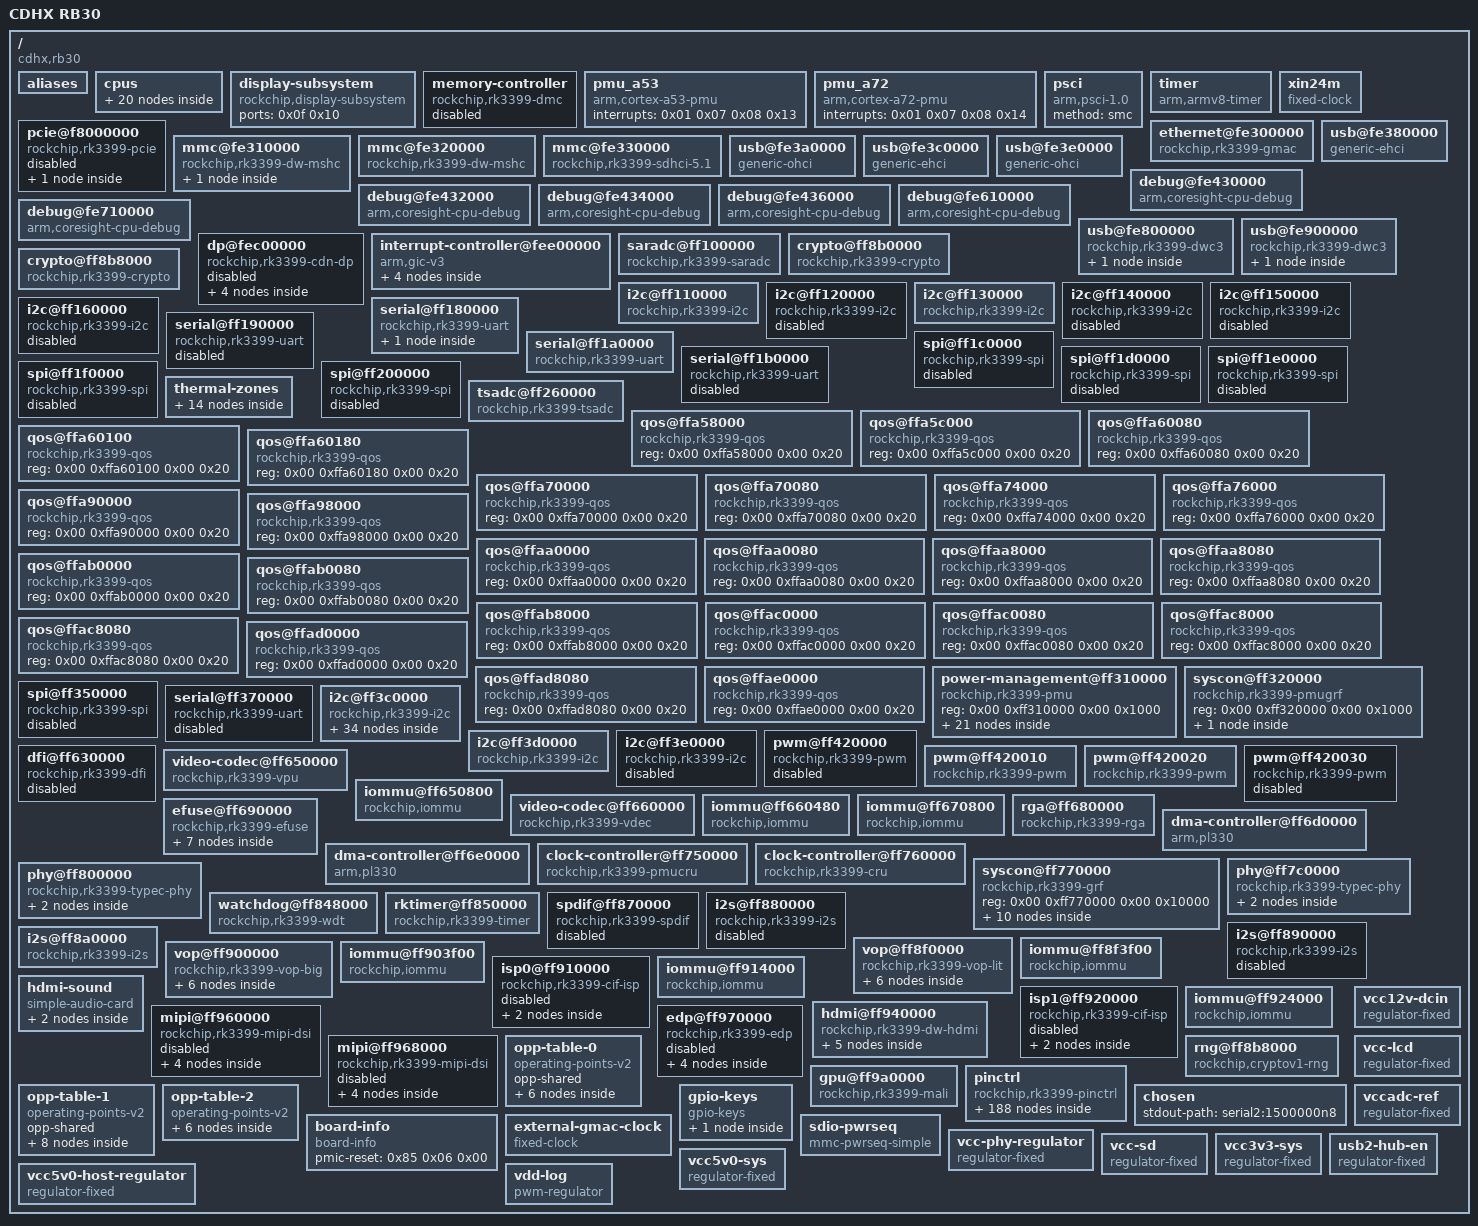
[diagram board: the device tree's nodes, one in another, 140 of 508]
/dts-v1/;

/ {
	compatible = "cdhx,rb30", "rockchip,rk3399";
	interrupt-parent = <0x01>;
	#address-cells = <0x02>;
	#size-cells = <0x02>;
	model = "CDHX RB30";

	aliases {
		ethernet0 = "/ethernet@fe300000";
		i2c0 = "/i2c@ff3c0000";
		i2c1 = "/i2c@ff110000";
		i2c2 = "/i2c@ff120000";
		i2c3 = "/i2c@ff130000";
		i2c4 = "/i2c@ff3d0000";
		i2c5 = "/i2c@ff140000";
		i2c6 = "/i2c@ff150000";
		i2c7 = "/i2c@ff160000";
		i2c8 = "/i2c@ff3e0000";
		mmc0 = "/mmc@fe310000";
		mmc1 = "/mmc@fe320000";
		mmc2 = "/mmc@fe330000";
		serial0 = "/serial@ff180000";
		serial1 = "/serial@ff190000";
		serial2 = "/serial@ff1a0000";
		serial3 = "/serial@ff1b0000";
		serial4 = "/serial@ff370000";
	};

	cpus {
		#address-cells = <0x02>;
		#size-cells = <0x00>;

		cpu-map {

			cluster0 {

				core0 {
					cpu = <0x02>;
				};

				core1 {
					cpu = <0x03>;
				};

				core2 {
					cpu = <0x04>;
				};

				core3 {
					cpu = <0x05>;
				};
			};

			cluster1 {

				core0 {
					cpu = <0x06>;
				};

				core1 {
					cpu = <0x07>;
				};
			};
		};

		cpu@0 {
			device_type = "cpu";
			compatible = "arm,cortex-a53";
			reg = <0x00 0x00>;
			enable-method = "psci";
			capacity-dmips-mhz = <0x1e5>;
			clocks = <0x08 0x08>;
			#cooling-cells = <0x02>;
			dynamic-power-coefficient = <0x64>;
			cpu-idle-states = <0x09 0x0a>;
			operating-points-v2 = <0x0b>;
			cpu-supply = <0x0c>;
			phandle = <0x02>;
		};

		cpu@1 {
			device_type = "cpu";
			compatible = "arm,cortex-a53";
			reg = <0x00 0x01>;
			enable-method = "psci";
			capacity-dmips-mhz = <0x1e5>;
			clocks = <0x08 0x08>;
			#cooling-cells = <0x02>;
			dynamic-power-coefficient = <0x64>;
			cpu-idle-states = <0x09 0x0a>;
			operating-points-v2 = <0x0b>;
			cpu-supply = <0x0c>;
			phandle = <0x03>;
		};

		cpu@2 {
			device_type = "cpu";
			compatible = "arm,cortex-a53";
			reg = <0x00 0x02>;
			enable-method = "psci";
			capacity-dmips-mhz = <0x1e5>;
			clocks = <0x08 0x08>;
			#cooling-cells = <0x02>;
			dynamic-power-coefficient = <0x64>;
			cpu-idle-states = <0x09 0x0a>;
			operating-points-v2 = <0x0b>;
			cpu-supply = <0x0c>;
			phandle = <0x04>;
		};

		cpu@3 {
			device_type = "cpu";
			compatible = "arm,cortex-a53";
			reg = <0x00 0x03>;
			enable-method = "psci";
			capacity-dmips-mhz = <0x1e5>;
			clocks = <0x08 0x08>;
			#cooling-cells = <0x02>;
			dynamic-power-coefficient = <0x64>;
			cpu-idle-states = <0x09 0x0a>;
			operating-points-v2 = <0x0b>;
			cpu-supply = <0x0c>;
			phandle = <0x05>;
		};

		cpu@100 {
			device_type = "cpu";
			compatible = "arm,cortex-a72";
			reg = <0x00 0x100>;
			enable-method = "psci";
			capacity-dmips-mhz = <0x400>;
			clocks = <0x08 0x09>;
			#cooling-cells = <0x02>;
			dynamic-power-coefficient = <0x1b4>;
			cpu-idle-states = <0x09 0x0a>;
			operating-points-v2 = <0x0d>;
			cpu-supply = <0x0e>;
			phandle = <0x06>;

			thermal-idle {
				#cooling-cells = <0x02>;
				duration-us = <0x2710>;
				exit-latency-us = <0x1f4>;
			};
		};

		cpu@101 {
			device_type = "cpu";
			compatible = "arm,cortex-a72";
			reg = <0x00 0x101>;
			enable-method = "psci";
			capacity-dmips-mhz = <0x400>;
			clocks = <0x08 0x09>;
			#cooling-cells = <0x02>;
			dynamic-power-coefficient = <0x1b4>;
			cpu-idle-states = <0x09 0x0a>;
			operating-points-v2 = <0x0d>;
			cpu-supply = <0x0e>;
			phandle = <0x07>;

			thermal-idle {
				#cooling-cells = <0x02>;
				duration-us = <0x2710>;
				exit-latency-us = <0x1f4>;
			};
		};

		idle-states {
			entry-method = "psci";

			cpu-sleep {
				compatible = "arm,idle-state";
				local-timer-stop;
				arm,psci-suspend-param = <0x10000>;
				entry-latency-us = <0x78>;
				exit-latency-us = <0xfa>;
				min-residency-us = <0x384>;
				phandle = <0x09>;
			};

			cluster-sleep {
				compatible = "arm,idle-state";
				local-timer-stop;
				arm,psci-suspend-param = <0x1010000>;
				entry-latency-us = <0x190>;
				exit-latency-us = <0x1f4>;
				min-residency-us = <0x7d0>;
				phandle = <0x0a>;
			};
		};
	};

	display-subsystem {
		compatible = "rockchip,display-subsystem";
		ports = <0x0f 0x10>;
	};

	memory-controller {
		compatible = "rockchip,rk3399-dmc";
		rockchip,pmu = <0x11>;
		devfreq-events = <0x12>;
		clocks = <0x08 0xa8>;
		clock-names = "dmc_clk";
		status = "disabled";
		phandle = <0xc7>;
	};

	pmu_a53 {
		compatible = "arm,cortex-a53-pmu";
		interrupts = <0x01 0x07 0x08 0x13>;
	};

	pmu_a72 {
		compatible = "arm,cortex-a72-pmu";
		interrupts = <0x01 0x07 0x08 0x14>;
	};

	psci {
		compatible = "arm,psci-1.0";
		method = "smc";
	};

	timer {
		compatible = "arm,armv8-timer";
		interrupts = <0x01 0x0d 0x08 0x00 0x01 0x0e 0x08 0x00 0x01 0x0b 0x08 0x00 0x01 0x0a 0x08 0x00>;
		arm,no-tick-in-suspend;
	};

	xin24m {
		compatible = "fixed-clock";
		clock-frequency = <0x16e3600>;
		clock-output-names = "xin24m";
		#clock-cells = <0x00>;
		phandle = <0x92>;
	};

	pcie@f8000000 {
		compatible = "rockchip,rk3399-pcie";
		reg = <0x00 0xf8000000 0x00 0x2000000 0x00 0xfd000000 0x00 0x1000000>;
		reg-names = "axi-base", "apb-base";
		device_type = "pci";
		#address-cells = <0x03>;
		#size-cells = <0x02>;
		#interrupt-cells = <0x01>;
		aspm-no-l0s;
		bus-range = <0x00 0x1f>;
		clocks = <0x08 0xc5 0x08 0xc4 0x08 0x147 0x08 0xa0>;
		clock-names = "aclk", "aclk-perf", "hclk", "pm";
		interrupts = <0x00 0x31 0x04 0x00 0x00 0x32 0x04 0x00 0x00 0x33 0x04 0x00>;
		interrupt-names = "sys", "legacy", "client";
		interrupt-map-mask = <0x00 0x00 0x00 0x07>;
		interrupt-map = <0x00 0x00 0x00 0x01 0x15 0x00 0x00 0x00 0x00 0x02 0x15 0x01 0x00 0x00 0x00 0x03 0x15 0x02 0x00 0x00 0x00 0x04 0x15 0x03>;
		max-link-speed = <0x01>;
		msi-map = <0x00 0x16 0x00 0x1000>;
		phys = <0x17 0x00 0x17 0x01 0x17 0x02 0x17 0x03>;
		phy-names = "pcie-phy-0", "pcie-phy-1", "pcie-phy-2", "pcie-phy-3";
		ranges = <0x82000000 0x00 0xfa000000 0x00 0xfa000000 0x00 0x1e00000 0x81000000 0x00 0xfbe00000 0x00 0xfbe00000 0x00 0x100000>;
		resets = <0x08 0x82 0x08 0x83 0x08 0x84 0x08 0x85 0x08 0x86 0x08 0x81 0x08 0x80>;
		reset-names = "core", "mgmt", "mgmt-sticky", "pipe", "pm", "pclk", "aclk";
		status = "disabled";
		phandle = <0xc8>;

		interrupt-controller {
			interrupt-controller;
			#address-cells = <0x00>;
			#interrupt-cells = <0x01>;
			phandle = <0x15>;
		};
	};

	ethernet@fe300000 {
		compatible = "rockchip,rk3399-gmac";
		reg = <0x00 0xfe300000 0x00 0x10000>;
		interrupts = <0x00 0x0c 0x04 0x00>;
		interrupt-names = "macirq";
		clocks = <0x08 0x69 0x08 0x67 0x08 0x68 0x08 0x66 0x08 0x6a 0x08 0xd5 0x08 0x166>;
		clock-names = "stmmaceth", "mac_clk_rx", "mac_clk_tx", "clk_mac_ref", "clk_mac_refout", "aclk_mac", "pclk_mac";
		power-domains = <0x18 0x16>;
		resets = <0x08 0x89>;
		reset-names = "stmmaceth";
		rockchip,grf = <0x19>;
		snps,txpbl = <0x04>;
		status = "okay";
		assigned-clocks = <0x08 0xa6>;
		assigned-clock-parents = <0x1a>;
		clock_in_out = "input";
		phy-supply = <0x1b>;
		phy-mode = "rgmii";
		pinctrl-names = "default";
		pinctrl-0 = <0x1c>;
		snps,reset-gpio = <0x1d 0x0f 0x01>;
		snps,reset-active-low;
		snps,reset-delays-us = <0x00 0x2710 0xc350>;
		tx_delay = <0x28>;
		rx_delay = <0x11>;
		phandle = <0xc9>;
	};

	mmc@fe310000 {
		compatible = "rockchip,rk3399-dw-mshc", "rockchip,rk3288-dw-mshc";
		reg = <0x00 0xfe310000 0x00 0x4000>;
		interrupts = <0x00 0x40 0x04 0x00>;
		max-frequency = <0x8f0d180>;
		clocks = <0x08 0x1ee 0x08 0x4d 0x08 0x9c 0x08 0x9d>;
		clock-names = "biu", "ciu", "ciu-drive", "ciu-sample";
		fifo-depth = <0x100>;
		power-domains = <0x18 0x1c>;
		resets = <0x08 0x79>;
		reset-names = "reset";
		status = "okay";
		#address-cells = <0x01>;
		#size-cells = <0x00>;
		bus-width = <0x04>;
		clock-frequency = <0x2faf080>;
		cap-sdio-irq;
		cap-sd-highspeed;
		keep-power-in-suspend;
		mmc-pwrseq = <0x1e>;
		non-removable;
		pinctrl-names = "default";
		pinctrl-0 = <0x1f 0x20 0x21>;
		sd-uhs-sdr104;
		phandle = <0xca>;

		wifi@1 {
			compatible = "brcm,bcm43455-fmac";
			reg = <0x01>;
			interrupt-parent = <0x22>;
			interrupts = <0x03 0x00>;
			interrupt-names = "host-wake";
			pinctrl-names = "default";
			pinctrl-0 = <0x23>;
			phandle = <0xcb>;
		};
	};

	mmc@fe320000 {
		compatible = "rockchip,rk3399-dw-mshc", "rockchip,rk3288-dw-mshc";
		reg = <0x00 0xfe320000 0x00 0x4000>;
		interrupts = <0x00 0x41 0x04 0x00>;
		max-frequency = <0x8f0d180>;
		assigned-clocks = <0x08 0x1cd>;
		assigned-clock-rates = <0xbebc200>;
		clocks = <0x08 0x1ce 0x08 0x4c 0x08 0x9a 0x08 0x9b>;
		clock-names = "biu", "ciu", "ciu-drive", "ciu-sample";
		fifo-depth = <0x100>;
		power-domains = <0x18 0x1b>;
		resets = <0x08 0x7a>;
		reset-names = "reset";
		status = "okay";
		clock-frequency = <0x8f0d180>;
		clock-freq-min-max = <0x186a0 0x8f0d180>;
		supports-sd;
		bus-width = <0x04>;
		cap-mmc-highspeed;
		cap-sd-highspeed;
		disable-wp;
		num-slots = <0x01>;
		sd-uhs-sdr104;
		vmmc-supply = <0x24>;
		vqmmc-supply = <0x25>;
		pinctrl-names = "default";
		pinctrl-0 = <0x26 0x27 0x28 0x29>;
		phandle = <0xcc>;
	};

	mmc@fe330000 {
		compatible = "rockchip,rk3399-sdhci-5.1", "arasan,sdhci-5.1";
		reg = <0x00 0xfe330000 0x00 0x10000>;
		interrupts = <0x00 0x0b 0x04 0x00>;
		arasan,soc-ctl-syscon = <0x19>;
		assigned-clocks = <0x08 0x4e>;
		assigned-clock-rates = <0xbebc200>;
		clocks = <0x08 0x4e 0x08 0xf0>;
		clock-names = "clk_xin", "clk_ahb";
		clock-output-names = "emmc_cardclock";
		#clock-cells = <0x00>;
		phys = <0x2a>;
		phy-names = "phy_arasan";
		power-domains = <0x18 0x17>;
		disable-cqe-dcmd;
		status = "okay";
		bus-width = <0x08>;
		mmc-hs200-enhanced-strobe;
		non-removable;
		phandle = <0x95>;
	};

	usb@fe380000 {
		compatible = "generic-ehci";
		reg = <0x00 0xfe380000 0x00 0x20000>;
		interrupts = <0x00 0x1a 0x04 0x00>;
		clocks = <0x08 0x1c8 0x08 0x1c9 0x2b>;
		phys = <0x2c>;
		phy-names = "usb";
		status = "okay";
		phandle = <0xcd>;
	};

	usb@fe3a0000 {
		compatible = "generic-ohci";
		reg = <0x00 0xfe3a0000 0x00 0x20000>;
		interrupts = <0x00 0x1c 0x04 0x00>;
		clocks = <0x08 0x1c8 0x08 0x1c9 0x2b>;
		phys = <0x2c>;
		phy-names = "usb";
		status = "okay";
		phandle = <0xce>;
	};

	usb@fe3c0000 {
		compatible = "generic-ehci";
		reg = <0x00 0xfe3c0000 0x00 0x20000>;
		interrupts = <0x00 0x1e 0x04 0x00>;
		clocks = <0x08 0x1ca 0x08 0x1cb 0x2d>;
		phys = <0x2e>;
		phy-names = "usb";
		status = "okay";
		phandle = <0xcf>;
	};

	usb@fe3e0000 {
		compatible = "generic-ohci";
		reg = <0x00 0xfe3e0000 0x00 0x20000>;
		interrupts = <0x00 0x20 0x04 0x00>;
		clocks = <0x08 0x1ca 0x08 0x1cb 0x2d>;
		phys = <0x2e>;
		phy-names = "usb";
		status = "okay";
		phandle = <0xd0>;
	};

	debug@fe430000 {
		compatible = "arm,coresight-cpu-debug", "arm,primecell";
		reg = <0x00 0xfe430000 0x00 0x1000>;
		clocks = <0x08 0x14d>;
		clock-names = "apb_pclk";
		cpu = <0x02>;
	};

	debug@fe432000 {
		compatible = "arm,coresight-cpu-debug", "arm,primecell";
		reg = <0x00 0xfe432000 0x00 0x1000>;
		clocks = <0x08 0x14d>;
		clock-names = "apb_pclk";
		cpu = <0x03>;
	};

	debug@fe434000 {
		compatible = "arm,coresight-cpu-debug", "arm,primecell";
		reg = <0x00 0xfe434000 0x00 0x1000>;
		clocks = <0x08 0x14d>;
		clock-names = "apb_pclk";
		cpu = <0x04>;
	};

	debug@fe436000 {
		compatible = "arm,coresight-cpu-debug", "arm,primecell";
		reg = <0x00 0xfe436000 0x00 0x1000>;
		clocks = <0x08 0x14d>;
		clock-names = "apb_pclk";
		cpu = <0x05>;
	};

	debug@fe610000 {
		compatible = "arm,coresight-cpu-debug", "arm,primecell";
		reg = <0x00 0xfe610000 0x00 0x1000>;
		clocks = <0x08 0x14c>;
		clock-names = "apb_pclk";
		cpu = <0x06>;
	};

	debug@fe710000 {
		compatible = "arm,coresight-cpu-debug", "arm,primecell";
		reg = <0x00 0xfe710000 0x00 0x1000>;
		clocks = <0x08 0x14c>;
		clock-names = "apb_pclk";
		cpu = <0x07>;
	};

	usb@fe800000 {
		compatible = "rockchip,rk3399-dwc3";
		#address-cells = <0x02>;
		#size-cells = <0x02>;
		ranges;
		clocks = <0x08 0x81 0x08 0x83 0x08 0xf6 0x08 0xf8 0x08 0xf4 0x08 0xf9>;
		clock-names = "ref_clk", "suspend_clk", "bus_clk", "aclk_usb3_rksoc_axi_perf", "aclk_usb3", "grf_clk";
		resets = <0x08 0x125>;
		reset-names = "usb3-otg";
		status = "okay";
		phandle = <0xd1>;

		usb@fe800000 {
			compatible = "snps,dwc3";
			reg = <0x00 0xfe800000 0x00 0x100000>;
			interrupts = <0x00 0x69 0x04 0x00>;
			clocks = <0x08 0x81 0x08 0xf6 0x08 0x83>;
			clock-names = "ref", "bus_early", "suspend";
			dr_mode = "host";
			phys = <0x2f 0x30>;
			phy-names = "usb2-phy", "usb3-phy";
			phy_type = "utmi_wide";
			snps,dis_enblslpm_quirk;
			snps,dis-u2-freeclk-exists-quirk;
			snps,dis_u2_susphy_quirk;
			snps,dis-del-phy-power-chg-quirk;
			snps,dis-tx-ipgap-linecheck-quirk;
			power-domains = <0x18 0x18>;
			status = "okay";
			phandle = <0xd2>;
		};
	};

	usb@fe900000 {
		compatible = "rockchip,rk3399-dwc3";
		#address-cells = <0x02>;
		#size-cells = <0x02>;
		ranges;
		clocks = <0x08 0x82 0x08 0x84 0x08 0xf7 0x08 0xf8 0x08 0xf4 0x08 0xf9>;
		clock-names = "ref_clk", "suspend_clk", "bus_clk", "aclk_usb3_rksoc_axi_perf", "aclk_usb3", "grf_clk";
		resets = <0x08 0x126>;
		reset-names = "usb3-otg";
		status = "okay";
		phandle = <0xd3>;

		usb@fe900000 {
			compatible = "snps,dwc3";
			reg = <0x00 0xfe900000 0x00 0x100000>;
			interrupts = <0x00 0x6e 0x04 0x00>;
			clocks = <0x08 0x82 0x08 0xf7 0x08 0x84>;
			clock-names = "ref", "bus_early", "suspend";
			dr_mode = "host";
			phys = <0x31 0x32>;
			phy-names = "usb2-phy", "usb3-phy";
			phy_type = "utmi_wide";
			snps,dis_enblslpm_quirk;
			snps,dis-u2-freeclk-exists-quirk;
			snps,dis_u2_susphy_quirk;
			snps,dis-del-phy-power-chg-quirk;
			snps,dis-tx-ipgap-linecheck-quirk;
			power-domains = <0x18 0x18>;
			status = "okay";
			phandle = <0xd4>;
		};
	};

	dp@fec00000 {
		compatible = "rockchip,rk3399-cdn-dp";
		reg = <0x00 0xfec00000 0x00 0x100000>;
		interrupts = <0x00 0x09 0x04 0x00>;
		assigned-clocks = <0x08 0x72 0x08 0xa1>;
		assigned-clock-rates = <0x5f5e100 0xbebc200>;
		clocks = <0x08 0x72 0x08 0x175 0x08 0xa1 0x08 0x16f>;
		clock-names = "core-clk", "pclk", "spdif", "grf";
		phys = <0x33 0x34>;
		power-domains = <0x18 0x15>;
		resets = <0x08 0x103 0x08 0x148 0x08 0x14a 0x08 0xfd>;
		reset-names = "spdif", "dptx", "apb", "core";
		rockchip,grf = <0x19>;
		#sound-dai-cells = <0x01>;
		status = "disabled";
		phandle = <0xd5>;

		ports {

			port {
				#address-cells = <0x01>;
				#size-cells = <0x00>;
				phandle = <0xd6>;

				endpoint@0 {
					reg = <0x00>;
					remote-endpoint = <0x35>;
					phandle = <0xa5>;
				};

				endpoint@1 {
					reg = <0x01>;
					remote-endpoint = <0x36>;
					phandle = <0x9f>;
				};
			};
		};
	};

	interrupt-controller@fee00000 {
		compatible = "arm,gic-v3";
		#interrupt-cells = <0x04>;
		#address-cells = <0x02>;
		#size-cells = <0x02>;
		ranges;
		interrupt-controller;
		reg = <0x00 0xfee00000 0x00 0x10000 0x00 0xfef00000 0x00 0xc0000 0x00 0xfff00000 0x00 0x10000 0x00 0xfff10000 0x00 0x10000 0x00 0xfff20000 0x00 0x10000>;
		interrupts = <0x01 0x09 0x04 0x00>;
		phandle = <0x01>;

		interrupt-controller@fee20000 {
			compatible = "arm,gic-v3-its";
			msi-controller;
			#msi-cells = <0x01>;
			reg = <0x00 0xfee20000 0x00 0x20000>;
			phandle = <0x16>;
		};

		ppi-partitions {

			interrupt-partition-0 {
				affinity = <0x02 0x03 0x04 0x05>;
				phandle = <0x13>;
			};

			interrupt-partition-1 {
				affinity = <0x06 0x07>;
				phandle = <0x14>;
			};
		};
	};

	saradc@ff100000 {
		compatible = "rockchip,rk3399-saradc";
		reg = <0x00 0xff100000 0x00 0x100>;
		interrupts = <0x00 0x3e 0x04 0x00>;
		#io-channel-cells = <0x01>;
		clocks = <0x08 0x50 0x08 0x165>;
		clock-names = "saradc", "apb_pclk";
		resets = <0x08 0xd4>;
		reset-names = "saradc-apb";
		status = "okay";
		vref-supply = <0x37>;
		phandle = <0xd7>;
	};

	crypto@ff8b0000 {
		compatible = "rockchip,rk3399-crypto";
		reg = <0x00 0xff8b0000 0x00 0x4000>;
		interrupts = <0x00 0x00 0x04 0x00>;
		clocks = <0x08 0x1d0 0x08 0x1d2 0x08 0x85>;
		clock-names = "hclk_master", "hclk_slave", "sclk";
		resets = <0x08 0xb5 0x08 0xae 0x08 0xaf>;
		reset-names = "master", "lave", "crypto";
		phandle = <0xd8>;
	};

	crypto@ff8b8000 {
		compatible = "rockchip,rk3399-crypto";
		reg = <0x00 0xff8b8000 0x00 0x4000>;
		interrupts = <0x00 0x87 0x04 0x00>;
		clocks = <0x08 0x1d1 0x08 0x1d3 0x08 0x86>;
		clock-names = "hclk_master", "hclk_slave", "sclk";
		resets = <0x08 0xba 0x08 0xb8 0x08 0xb9>;
		reset-names = "master", "slave", "crypto";
		phandle = <0xd9>;
	};

	i2c@ff110000 {
		compatible = "rockchip,rk3399-i2c";
		reg = <0x00 0xff110000 0x00 0x1000>;
		assigned-clocks = <0x08 0x41>;
		assigned-clock-rates = <0xbebc200>;
		clocks = <0x08 0x41 0x08 0x155>;
		clock-names = "i2c", "pclk";
		interrupts = <0x00 0x3b 0x04 0x00>;
		pinctrl-names = "default";
		pinctrl-0 = <0x38>;
		#address-cells = <0x01>;
		#size-cells = <0x00>;
		status = "okay";
		i2c-scl-rising-time-ns = <0x12c>;
		i2c-scl-falling-time-ns = <0x0f>;
		phandle = <0xda>;
	};

	i2c@ff120000 {
		compatible = "rockchip,rk3399-i2c";
		reg = <0x00 0xff120000 0x00 0x1000>;
		assigned-clocks = <0x08 0x42>;
		assigned-clock-rates = <0xbebc200>;
		clocks = <0x08 0x42 0x08 0x156>;
		clock-names = "i2c", "pclk";
		interrupts = <0x00 0x23 0x04 0x00>;
		pinctrl-names = "default";
		pinctrl-0 = <0x39>;
		#address-cells = <0x01>;
		#size-cells = <0x00>;
		status = "disabled";
		phandle = <0xdb>;
	};

	i2c@ff130000 {
		compatible = "rockchip,rk3399-i2c";
		reg = <0x00 0xff130000 0x00 0x1000>;
		assigned-clocks = <0x08 0x43>;
		assigned-clock-rates = <0xbebc200>;
		clocks = <0x08 0x43 0x08 0x157>;
		clock-names = "i2c", "pclk";
		interrupts = <0x00 0x22 0x04 0x00>;
		pinctrl-names = "default";
		pinctrl-0 = <0x3a>;
		#address-cells = <0x01>;
		#size-cells = <0x00>;
		status = "okay";
		i2c-scl-rising-time-ns = <0x1c2>;
		i2c-scl-falling-time-ns = <0x0f>;
		phandle = <0xac>;
	};

	i2c@ff140000 {
		compatible = "rockchip,rk3399-i2c";
		reg = <0x00 0xff140000 0x00 0x1000>;
		assigned-clocks = <0x08 0x44>;
		assigned-clock-rates = <0xbebc200>;
		clocks = <0x08 0x44 0x08 0x158>;
		clock-names = "i2c", "pclk";
		interrupts = <0x00 0x26 0x04 0x00>;
		pinctrl-names = "default";
		pinctrl-0 = <0x3b>;
		#address-cells = <0x01>;
		#size-cells = <0x00>;
		status = "disabled";
		phandle = <0xdc>;
	};

	i2c@ff150000 {
		compatible = "rockchip,rk3399-i2c";
		reg = <0x00 0xff150000 0x00 0x1000>;
		assigned-clocks = <0x08 0x45>;
		assigned-clock-rates = <0xbebc200>;
		clocks = <0x08 0x45 0x08 0x159>;
		clock-names = "i2c", "pclk";
		interrupts = <0x00 0x25 0x04 0x00>;
		pinctrl-names = "default";
		pinctrl-0 = <0x3c>;
		#address-cells = <0x01>;
		#size-cells = <0x00>;
		status = "disabled";
		phandle = <0xdd>;
	};

	i2c@ff160000 {
		compatible = "rockchip,rk3399-i2c";
		reg = <0x00 0xff160000 0x00 0x1000>;
		assigned-clocks = <0x08 0x46>;
		assigned-clock-rates = <0xbebc200>;
		clocks = <0x08 0x46 0x08 0x15a>;
		clock-names = "i2c", "pclk";
		interrupts = <0x00 0x24 0x04 0x00>;
		pinctrl-names = "default";
		pinctrl-0 = <0x3d>;
		#address-cells = <0x01>;
		#size-cells = <0x00>;
		status = "disabled";
		phandle = <0xde>;
	};

	serial@ff180000 {
		compatible = "rockchip,rk3399-uart", "snps,dw-apb-uart";
		reg = <0x00 0xff180000 0x00 0x100>;
		clocks = <0x08 0x51 0x08 0x160>;
		clock-names = "baudclk", "apb_pclk";
		interrupts = <0x00 0x63 0x04 0x00>;
		reg-shift = <0x02>;
		reg-io-width = <0x04>;
		pinctrl-names = "default";
		pinctrl-0 = <0x3e 0x3f 0x40>;
		status = "okay";
		phandle = <0xdf>;

		bluetooth {
			compatible = "brcm,bcm43438-bt";
			clocks = <0x41 0x01>;
			clock-names = "lpo";
			device-wakeup-gpios = <0x42 0x1a 0x00>;
			host-wakeup-gpios = <0x22 0x04 0x00>;
			shutdown-gpios = <0x22 0x09 0x00>;
			pinctrl-names = "default";
			pinctrl-0 = <0x43 0x44 0x45>;
			vbat-supply = <0x46>;
			vddio-supply = <0x47>;
		};
	};

	serial@ff190000 {
		compatible = "rockchip,rk3399-uart", "snps,dw-apb-uart";
		reg = <0x00 0xff190000 0x00 0x100>;
		clocks = <0x08 0x52 0x08 0x161>;
		clock-names = "baudclk", "apb_pclk";
		interrupts = <0x00 0x62 0x04 0x00>;
		reg-shift = <0x02>;
		reg-io-width = <0x04>;
		pinctrl-names = "default";
		pinctrl-0 = <0x48>;
		status = "disabled";
		phandle = <0xe0>;
	};

	serial@ff1a0000 {
		compatible = "rockchip,rk3399-uart", "snps,dw-apb-uart";
		reg = <0x00 0xff1a0000 0x00 0x100>;
		clocks = <0x08 0x53 0x08 0x162>;
		clock-names = "baudclk", "apb_pclk";
		interrupts = <0x00 0x64 0x04 0x00>;
		reg-shift = <0x02>;
		reg-io-width = <0x04>;
		pinctrl-names = "default";
		pinctrl-0 = <0x49>;
		status = "okay";
		phandle = <0xe1>;
	};

	serial@ff1b0000 {
		compatible = "rockchip,rk3399-uart", "snps,dw-apb-uart";
		reg = <0x00 0xff1b0000 0x00 0x100>;
		clocks = <0x08 0x54 0x08 0x163>;
		clock-names = "baudclk", "apb_pclk";
		interrupts = <0x00 0x65 0x04 0x00>;
		reg-shift = <0x02>;
		reg-io-width = <0x04>;
		pinctrl-names = "default";
		pinctrl-0 = <0x4a>;
		status = "disabled";
		phandle = <0xe2>;
	};

	spi@ff1c0000 {
		compatible = "rockchip,rk3399-spi", "rockchip,rk3066-spi";
		reg = <0x00 0xff1c0000 0x00 0x1000>;
		clocks = <0x08 0x47 0x08 0x15b>;
		clock-names = "spiclk", "apb_pclk";
		interrupts = <0x00 0x44 0x04 0x00>;
		dmas = <0x4b 0x0a 0x4b 0x0b>;
		dma-names = "tx", "rx";
		pinctrl-names = "default";
		pinctrl-0 = <0x4c 0x4d 0x4e 0x4f>;
		#address-cells = <0x01>;
		#size-cells = <0x00>;
		status = "disabled";
		phandle = <0xe3>;
	};

	spi@ff1d0000 {
		compatible = "rockchip,rk3399-spi", "rockchip,rk3066-spi";
		reg = <0x00 0xff1d0000 0x00 0x1000>;
		clocks = <0x08 0x48 0x08 0x15c>;
		clock-names = "spiclk", "apb_pclk";
		interrupts = <0x00 0x35 0x04 0x00>;
		dmas = <0x4b 0x0c 0x4b 0x0d>;
		dma-names = "tx", "rx";
		pinctrl-names = "default";
		pinctrl-0 = <0x50 0x51 0x52 0x53>;
		#address-cells = <0x01>;
		#size-cells = <0x00>;
		status = "disabled";
		phandle = <0xe4>;
	};

	spi@ff1e0000 {
		compatible = "rockchip,rk3399-spi", "rockchip,rk3066-spi";
		reg = <0x00 0xff1e0000 0x00 0x1000>;
		clocks = <0x08 0x49 0x08 0x15d>;
		clock-names = "spiclk", "apb_pclk";
		interrupts = <0x00 0x34 0x04 0x00>;
		dmas = <0x4b 0x0e 0x4b 0x0f>;
		dma-names = "tx", "rx";
		pinctrl-names = "default";
		pinctrl-0 = <0x54 0x55 0x56 0x57>;
		#address-cells = <0x01>;
		#size-cells = <0x00>;
		status = "disabled";
		phandle = <0xe5>;
	};

	spi@ff1f0000 {
		compatible = "rockchip,rk3399-spi", "rockchip,rk3066-spi";
		reg = <0x00 0xff1f0000 0x00 0x1000>;
		clocks = <0x08 0x4a 0x08 0x15e>;
		clock-names = "spiclk", "apb_pclk";
		interrupts = <0x00 0x43 0x04 0x00>;
		dmas = <0x4b 0x12 0x4b 0x13>;
		dma-names = "tx", "rx";
		pinctrl-names = "default";
		pinctrl-0 = <0x58 0x59 0x5a 0x5b>;
		#address-cells = <0x01>;
		#size-cells = <0x00>;
		status = "disabled";
		phandle = <0xe6>;
	};

	spi@ff200000 {
		compatible = "rockchip,rk3399-spi", "rockchip,rk3066-spi";
		reg = <0x00 0xff200000 0x00 0x1000>;
		clocks = <0x08 0x4b 0x08 0x15f>;
		clock-names = "spiclk", "apb_pclk";
		interrupts = <0x00 0x84 0x04 0x00>;
		dmas = <0x5c 0x08 0x5c 0x09>;
		dma-names = "tx", "rx";
		pinctrl-names = "default";
		pinctrl-0 = <0x5d 0x5e 0x5f 0x60>;
		power-domains = <0x18 0x1c>;
		#address-cells = <0x01>;
		#size-cells = <0x00>;
		status = "disabled";
		phandle = <0xe7>;
	};

	thermal-zones {
		phandle = <0xe8>;

		cpu-thermal {
			polling-delay-passive = <0x64>;
			polling-delay = <0x3e8>;
			thermal-sensors = <0x61 0x00>;
			phandle = <0xe9>;

			trips {

				cpu_alert0 {
					temperature = <0x11170>;
					hysteresis = <0x7d0>;
					type = "passive";
					phandle = <0x62>;
				};

				cpu_alert1 {
					temperature = <0x124f8>;
					hysteresis = <0x7d0>;
					type = "passive";
					phandle = <0x63>;
				};

				cpu_crit {
					temperature = <0x17318>;
					hysteresis = <0x7d0>;
					type = "critical";
					phandle = <0xea>;
				};
			};

			cooling-maps {

				map0 {
					trip = <0x62>;
					cooling-device = <0x06 0xffffffff 0xffffffff 0x07 0xffffffff 0xffffffff>;
				};

				map1 {
					trip = <0x63>;
					cooling-device = <0x02 0xffffffff 0xffffffff 0x03 0xffffffff 0xffffffff 0x04 0xffffffff 0xffffffff 0x05 0xffffffff 0xffffffff 0x06 0xffffffff 0xffffffff 0x07 0xffffffff 0xffffffff>;
				};
			};
		};

		gpu-thermal {
			polling-delay-passive = <0x64>;
			polling-delay = <0x3e8>;
			thermal-sensors = <0x61 0x01>;
			phandle = <0xeb>;

			trips {

				gpu_alert0 {
					temperature = <0x124f8>;
					hysteresis = <0x7d0>;
					type = "passive";
					phandle = <0x64>;
				};

				gpu_crit {
					temperature = <0x17318>;
					hysteresis = <0x7d0>;
					type = "critical";
					phandle = <0xec>;
				};
			};

			cooling-maps {

				map0 {
					trip = <0x64>;
					cooling-device = <0x65 0xffffffff 0xffffffff>;
				};
			};
		};
	};

	tsadc@ff260000 {
		compatible = "rockchip,rk3399-tsadc";
		reg = <0x00 0xff260000 0x00 0x100>;
		interrupts = <0x00 0x61 0x04 0x00>;
		assigned-clocks = <0x08 0x4f>;
		assigned-clock-rates = <0xb71b0>;
		clocks = <0x08 0x4f 0x08 0x164>;
		clock-names = "tsadc", "apb_pclk";
		resets = <0x08 0xe8>;
		reset-names = "tsadc-apb";
		rockchip,grf = <0x19>;
		rockchip,hw-tshut-temp = <0x17318>;
		pinctrl-names = "init", "default", "sleep";
		pinctrl-0 = <0x66>;
		pinctrl-1 = <0x67>;
		pinctrl-2 = <0x66>;
		#thermal-sensor-cells = <0x01>;
		status = "okay";
		rockchip,hw-tshut-mode = <0x01>;
		rockchip,hw-tshut-polarity = <0x01>;
		phandle = <0x61>;
	};

	qos@ffa58000 {
		compatible = "rockchip,rk3399-qos", "syscon";
		reg = <0x00 0xffa58000 0x00 0x20>;
		phandle = <0x6f>;
	};

	qos@ffa5c000 {
		compatible = "rockchip,rk3399-qos", "syscon";
		reg = <0x00 0xffa5c000 0x00 0x20>;
		phandle = <0x70>;
	};

	qos@ffa60080 {
		compatible = "rockchip,rk3399-qos", "syscon";
		reg = <0x00 0xffa60080 0x00 0x20>;
		phandle = <0xed>;
	};

	qos@ffa60100 {
		compatible = "rockchip,rk3399-qos", "syscon";
		reg = <0x00 0xffa60100 0x00 0x20>;
		phandle = <0xee>;
	};

	qos@ffa60180 {
		compatible = "rockchip,rk3399-qos", "syscon";
		reg = <0x00 0xffa60180 0x00 0x20>;
		phandle = <0xef>;
	};

	qos@ffa70000 {
		compatible = "rockchip,rk3399-qos", "syscon";
		reg = <0x00 0xffa70000 0x00 0x20>;
		phandle = <0x73>;
	};

	qos@ffa70080 {
		compatible = "rockchip,rk3399-qos", "syscon";
		reg = <0x00 0xffa70080 0x00 0x20>;
		phandle = <0x74>;
	};

	qos@ffa74000 {
		compatible = "rockchip,rk3399-qos", "syscon";
		reg = <0x00 0xffa74000 0x00 0x20>;
		phandle = <0x71>;
	};

	qos@ffa76000 {
		compatible = "rockchip,rk3399-qos", "syscon";
		reg = <0x00 0xffa76000 0x00 0x20>;
		phandle = <0x72>;
	};

	qos@ffa90000 {
		compatible = "rockchip,rk3399-qos", "syscon";
		reg = <0x00 0xffa90000 0x00 0x20>;
		phandle = <0x75>;
	};

	qos@ffa98000 {
		compatible = "rockchip,rk3399-qos", "syscon";
		reg = <0x00 0xffa98000 0x00 0x20>;
		phandle = <0x68>;
	};

	qos@ffaa0000 {
		compatible = "rockchip,rk3399-qos", "syscon";
		reg = <0x00 0xffaa0000 0x00 0x20>;
		phandle = <0x76>;
	};

	qos@ffaa0080 {
		compatible = "rockchip,rk3399-qos", "syscon";
		reg = <0x00 0xffaa0080 0x00 0x20>;
		phandle = <0x77>;
	};

	qos@ffaa8000 {
		compatible = "rockchip,rk3399-qos", "syscon";
		reg = <0x00 0xffaa8000 0x00 0x20>;
		phandle = <0x78>;
	};

	qos@ffaa8080 {
		compatible = "rockchip,rk3399-qos", "syscon";
		reg = <0x00 0xffaa8080 0x00 0x20>;
		phandle = <0x79>;
	};

	qos@ffab0000 {
		compatible = "rockchip,rk3399-qos", "syscon";
		reg = <0x00 0xffab0000 0x00 0x20>;
		phandle = <0x69>;
	};

	qos@ffab0080 {
		compatible = "rockchip,rk3399-qos", "syscon";
		reg = <0x00 0xffab0080 0x00 0x20>;
		phandle = <0x6a>;
	};

	qos@ffab8000 {
		compatible = "rockchip,rk3399-qos", "syscon";
		reg = <0x00 0xffab8000 0x00 0x20>;
		phandle = <0x6b>;
	};

	qos@ffac0000 {
		compatible = "rockchip,rk3399-qos", "syscon";
		reg = <0x00 0xffac0000 0x00 0x20>;
		phandle = <0x6c>;
	};

	qos@ffac0080 {
		compatible = "rockchip,rk3399-qos", "syscon";
		reg = <0x00 0xffac0080 0x00 0x20>;
		phandle = <0x6d>;
	};

	qos@ffac8000 {
		compatible = "rockchip,rk3399-qos", "syscon";
		reg = <0x00 0xffac8000 0x00 0x20>;
		phandle = <0x7a>;
	};

	qos@ffac8080 {
		compatible = "rockchip,rk3399-qos", "syscon";
		reg = <0x00 0xffac8080 0x00 0x20>;
		phandle = <0x7b>;
	};

	qos@ffad0000 {
		compatible = "rockchip,rk3399-qos", "syscon";
		reg = <0x00 0xffad0000 0x00 0x20>;
		phandle = <0x7c>;
	};

	qos@ffad8080 {
		compatible = "rockchip,rk3399-qos", "syscon";
		reg = <0x00 0xffad8080 0x00 0x20>;
		phandle = <0xf0>;
	};

	qos@ffae0000 {
		compatible = "rockchip,rk3399-qos", "syscon";
		reg = <0x00 0xffae0000 0x00 0x20>;
		phandle = <0x6e>;
	};

	power-management@ff310000 {
		compatible = "rockchip,rk3399-pmu", "syscon", "simple-mfd";
		reg = <0x00 0xff310000 0x00 0x1000>;
		phandle = <0xf1>;

		power-controller {
			compatible = "rockchip,rk3399-power-controller";
			#power-domain-cells = <0x01>;
			#address-cells = <0x01>;
			#size-cells = <0x00>;
			phandle = <0x18>;

			power-domain@34 {
				reg = <0x22>;
				clocks = <0x08 0xe1 0x08 0x1dd>;
				pm_qos = <0x68>;
				#power-domain-cells = <0x00>;
			};

			power-domain@33 {
				reg = <0x21>;
				clocks = <0x08 0xdc 0x08 0x1e5>;
				pm_qos = <0x69 0x6a>;
				#power-domain-cells = <0x00>;
			};

			power-domain@31 {
				reg = <0x1f>;
				clocks = <0x08 0xeb 0x08 0x1ea>;
				pm_qos = <0x6b>;
				#power-domain-cells = <0x00>;
			};

			power-domain@32 {
				reg = <0x20>;
				clocks = <0x08 0xed 0x08 0x1ec 0x08 0x9f 0x08 0x9e>;
				pm_qos = <0x6c 0x6d>;
				#power-domain-cells = <0x00>;
			};

			power-domain@35 {
				reg = <0x23>;
				clocks = <0x08 0xd0>;
				pm_qos = <0x6e>;
				#power-domain-cells = <0x00>;
			};

			power-domain@25 {
				reg = <0x19>;
				clocks = <0x08 0x16c>;
				#power-domain-cells = <0x00>;
			};

			power-domain@23 {
				reg = <0x17>;
				clocks = <0x08 0xf0>;
				pm_qos = <0x6f>;
				#power-domain-cells = <0x00>;
			};

			power-domain@22 {
				reg = <0x16>;
				clocks = <0x08 0xd5 0x08 0x166>;
				pm_qos = <0x70>;
				#power-domain-cells = <0x00>;
			};

			power-domain@27 {
				reg = <0x1b>;
				clocks = <0x08 0x1ce 0x08 0x4c>;
				pm_qos = <0x71>;
				#power-domain-cells = <0x00>;
			};

			power-domain@28 {
				reg = <0x1c>;
				clocks = <0x08 0x1ee>;
				pm_qos = <0x72>;
				#power-domain-cells = <0x00>;
			};

			power-domain@8 {
				reg = <0x08>;
				clocks = <0x08 0x7e 0x08 0x7d>;
				#power-domain-cells = <0x00>;
			};

			power-domain@9 {
				reg = <0x09>;
				clocks = <0x08 0x80 0x08 0x7f>;
				#power-domain-cells = <0x00>;
			};

			power-domain@24 {
				reg = <0x18>;
				clocks = <0x08 0xf4>;
				pm_qos = <0x73 0x74>;
				#power-domain-cells = <0x00>;
			};

			power-domain@15 {
				reg = <0x0f>;
				#power-domain-cells = <0x01>;
				#address-cells = <0x01>;
				#size-cells = <0x00>;

				power-domain@21 {
					reg = <0x15>;
					clocks = <0x08 0xde 0x08 0x1e7 0x08 0x172>;
					pm_qos = <0x75>;
					#power-domain-cells = <0x00>;
				};

				power-domain@19 {
					reg = <0x13>;
					clocks = <0x08 0xe5 0x08 0x1df>;
					pm_qos = <0x76 0x77>;
					#power-domain-cells = <0x00>;
				};

				power-domain@20 {
					reg = <0x14>;
					clocks = <0x08 0xe6 0x08 0x1e0>;
					pm_qos = <0x78 0x79>;
					#power-domain-cells = <0x00>;
				};

				power-domain@16 {
					reg = <0x10>;
					#power-domain-cells = <0x01>;
					#address-cells = <0x01>;
					#size-cells = <0x00>;

					power-domain@17 {
						reg = <0x11>;
						clocks = <0x08 0xd9 0x08 0x1d9>;
						pm_qos = <0x7a 0x7b>;
						#power-domain-cells = <0x00>;
					};

					power-domain@18 {
						reg = <0x12>;
						clocks = <0x08 0xdb 0x08 0x1db>;
						pm_qos = <0x7c>;
						#power-domain-cells = <0x00>;
					};
				};
			};
		};
	};

	syscon@ff320000 {
		compatible = "rockchip,rk3399-pmugrf", "syscon", "simple-mfd";
		reg = <0x00 0xff320000 0x00 0x1000>;
		phandle = <0x11>;

		io-domains {
			compatible = "rockchip,rk3399-pmu-io-voltage-domain";
			status = "okay";
			pmu1830-supply = <0x7d>;
			phandle = <0xf2>;
		};
	};

	spi@ff350000 {
		compatible = "rockchip,rk3399-spi", "rockchip,rk3066-spi";
		reg = <0x00 0xff350000 0x00 0x1000>;
		clocks = <0x7e 0x03 0x7e 0x1f>;
		clock-names = "spiclk", "apb_pclk";
		interrupts = <0x00 0x3c 0x04 0x00>;
		pinctrl-names = "default";
		pinctrl-0 = <0x7f 0x80 0x81 0x82>;
		#address-cells = <0x01>;
		#size-cells = <0x00>;
		status = "disabled";
		phandle = <0xf3>;
	};

	serial@ff370000 {
		compatible = "rockchip,rk3399-uart", "snps,dw-apb-uart";
		reg = <0x00 0xff370000 0x00 0x100>;
		clocks = <0x7e 0x06 0x7e 0x22>;
		clock-names = "baudclk", "apb_pclk";
		interrupts = <0x00 0x66 0x04 0x00>;
		reg-shift = <0x02>;
		reg-io-width = <0x04>;
		pinctrl-names = "default";
		pinctrl-0 = <0x83>;
		status = "disabled";
		phandle = <0xf4>;
	};

	i2c@ff3c0000 {
		compatible = "rockchip,rk3399-i2c";
		reg = <0x00 0xff3c0000 0x00 0x1000>;
		assigned-clocks = <0x7e 0x09>;
		assigned-clock-rates = <0xbebc200>;
		clocks = <0x7e 0x09 0x7e 0x1b>;
		clock-names = "i2c", "pclk";
		interrupts = <0x00 0x39 0x04 0x00>;
		pinctrl-names = "default";
		pinctrl-0 = <0x84>;
		#address-cells = <0x01>;
		#size-cells = <0x00>;
		status = "okay";
		clock-frequency = <0x61a80>;
		i2c-scl-rising-time-ns = <0xa8>;
		i2c-scl-falling-time-ns = <0x04>;
		phandle = <0xf5>;

		pmic@1b {
			compatible = "rockchip,rk808";
			reg = <0x1b>;
			interrupt-parent = <0x85>;
			interrupts = <0x15 0x08>;
			#clock-cells = <0x01>;
			clock-output-names = "xin32k", "rk808-clkout2";
			pinctrl-names = "default";
			pinctrl-0 = <0x86>;
			rockchip,system-power-controller;
			wakeup-source;
			vcc1-supply = <0x46>;
			vcc2-supply = <0x46>;
			vcc3-supply = <0x46>;
			vcc4-supply = <0x46>;
			vcc6-supply = <0x46>;
			vcc7-supply = <0x46>;
			vcc8-supply = <0x46>;
			vcc9-supply = <0x46>;
			vcc10-supply = <0x46>;
			vcc11-supply = <0x46>;
			vcc12-supply = <0x46>;
			vddio-supply = <0x47>;
			phandle = <0x41>;

			regulators {

				DCDC_REG1 {
					regulator-name = "vdd_center";
					regulator-always-on;
					regulator-boot-on;
					regulator-min-microvolt = <0xb71b0>;
					regulator-max-microvolt = <0x149970>;
					regulator-ramp-delay = <0x1771>;
					phandle = <0xf6>;

					regulator-state-mem {
						regulator-off-in-suspend;
					};
				};

				DCDC_REG2 {
					regulator-name = "vdd_cpu_l";
					regulator-always-on;
					regulator-boot-on;
					regulator-min-microvolt = <0xb71b0>;
					regulator-max-microvolt = <0x149970>;
					regulator-ramp-delay = <0x1771>;
					phandle = <0x0c>;

					regulator-state-mem {
						regulator-off-in-suspend;
					};
				};

				DCDC_REG3 {
					regulator-name = "vcc_ddr";
					regulator-always-on;
					regulator-boot-on;
					phandle = <0xf7>;

					regulator-state-mem {
						regulator-on-in-suspend;
					};
				};

				DCDC_REG4 {
					regulator-name = "vcc_1v8";
					regulator-always-on;
					regulator-boot-on;
					regulator-min-microvolt = <0x1b7740>;
					regulator-max-microvolt = <0x1b7740>;
					phandle = <0x47>;

					regulator-state-mem {
						regulator-on-in-suspend;
						regulator-suspend-microvolt = <0x1b7740>;
					};
				};

				LDO_REG1 {
					regulator-name = "vcc1v8_dvp";
					regulator-always-on;
					regulator-boot-on;
					regulator-min-microvolt = <0x1b7740>;
					regulator-max-microvolt = <0x1b7740>;
					phandle = <0xf8>;

					regulator-state-mem {
						regulator-off-in-suspend;
					};
				};

				LDO_REG2 {
					regulator-name = "vcc3v0_tp";
					regulator-min-microvolt = <0x2dc6c0>;
					regulator-max-microvolt = <0x2dc6c0>;
					phandle = <0xf9>;

					regulator-state-mem {
						regulator-off-in-suspend;
					};
				};

				LDO_REG3 {
					regulator-name = "vcc1v8_pmu";
					regulator-always-on;
					regulator-boot-on;
					regulator-min-microvolt = <0x1b7740>;
					regulator-max-microvolt = <0x1b7740>;
					phandle = <0xfa>;

					regulator-state-mem {
						regulator-on-in-suspend;
						regulator-suspend-microvolt = <0x1b7740>;
					};
				};

				LDO_REG4 {
					regulator-name = "vccio_sd";
					regulator-always-on;
					regulator-boot-on;
					regulator-min-microvolt = <0x1b7740>;
					regulator-max-microvolt = <0x325aa0>;
					phandle = <0x25>;

					regulator-state-mem {
						regulator-on-in-suspend;
						regulator-suspend-microvolt = <0x325aa0>;
					};
				};

				LDO_REG5 {
					regulator-name = "vcca3v0_codec";
					regulator-always-on;
					regulator-boot-on;
					regulator-min-microvolt = <0x2dc6c0>;
					regulator-max-microvolt = <0x2dc6c0>;
					phandle = <0xfb>;

					regulator-state-mem {
						regulator-off-in-suspend;
					};
				};

				LDO_REG6 {
					regulator-name = "vcc_1v5";
					regulator-always-on;
					regulator-boot-on;
					regulator-min-microvolt = <0x16e360>;
					regulator-max-microvolt = <0x16e360>;
					phandle = <0xfc>;

					regulator-state-mem {
						regulator-on-in-suspend;
						regulator-suspend-microvolt = <0x16e360>;
					};
				};

				LDO_REG7 {
					regulator-name = "vcca1v8_codec";
					regulator-always-on;
					regulator-boot-on;
					regulator-min-microvolt = <0x1b7740>;
					regulator-max-microvolt = <0x1b7740>;
					phandle = <0x93>;

					regulator-state-mem {
						regulator-off-in-suspend;
					};
				};

				LDO_REG8 {
					regulator-name = "vcc_3v0";
					regulator-always-on;
					regulator-boot-on;
					regulator-min-microvolt = <0x2dc6c0>;
					regulator-max-microvolt = <0x2dc6c0>;
					phandle = <0x7d>;

					regulator-state-mem {
						regulator-on-in-suspend;
						regulator-suspend-microvolt = <0x2dc6c0>;
					};
				};

				SWITCH_REG1 {
					regulator-name = "vcc3v3_s3";
					regulator-always-on;
					regulator-boot-on;
					phandle = <0xfd>;

					regulator-state-mem {
						regulator-off-in-suspend;
					};
				};

				SWITCH_REG2 {
					regulator-name = "vcc3v3_s0";
					regulator-always-on;
					regulator-boot-on;
					phandle = <0xfe>;

					regulator-state-mem {
						regulator-off-in-suspend;
					};
				};
			};
		};

		regulator@40 {
			compatible = "silergy,syr827";
			reg = <0x40>;
			fcs,suspend-voltage-selector = <0x01>;
			pinctrl-names = "default";
			pinctrl-0 = <0x87>;
			regulator-name = "vdd_cpu_b";
			regulator-min-microvolt = <0xadf34>;
			regulator-max-microvolt = <0x16e360>;
			regulator-ramp-delay = <0x3e8>;
			regulator-always-on;
			regulator-boot-on;
			vin-supply = <0x88>;
			phandle = <0x0e>;

			regulator-state-mem {
				regulator-off-in-suspend;
			};
		};

		regulator@41 {
			compatible = "silergy,syr828";
			reg = <0x41>;
			fcs,suspend-voltage-selector = <0x01>;
			pinctrl-names = "default";
			pinctrl-0 = <0x89>;
			regulator-name = "vdd_gpu";
			regulator-min-microvolt = <0xadf34>;
			regulator-max-microvolt = <0x16e360>;
			regulator-ramp-delay = <0x3e8>;
			regulator-always-on;
			regulator-boot-on;
			vin-supply = <0x88>;
			phandle = <0xb8>;

			regulator-state-mem {
				regulator-off-in-suspend;
			};
		};
	};

	i2c@ff3d0000 {
		compatible = "rockchip,rk3399-i2c";
		reg = <0x00 0xff3d0000 0x00 0x1000>;
		assigned-clocks = <0x7e 0x0a>;
		assigned-clock-rates = <0xbebc200>;
		clocks = <0x7e 0x0a 0x7e 0x1c>;
		clock-names = "i2c", "pclk";
		interrupts = <0x00 0x38 0x04 0x00>;
		pinctrl-names = "default";
		pinctrl-0 = <0x8a>;
		#address-cells = <0x01>;
		#size-cells = <0x00>;
		status = "okay";
		i2c-scl-rising-time-ns = <0x258>;
		i2c-scl-falling-time-ns = <0x14>;
		phandle = <0xff>;
	};

	i2c@ff3e0000 {
		compatible = "rockchip,rk3399-i2c";
		reg = <0x00 0xff3e0000 0x00 0x1000>;
		assigned-clocks = <0x7e 0x0b>;
		assigned-clock-rates = <0xbebc200>;
		clocks = <0x7e 0x0b 0x7e 0x1d>;
		clock-names = "i2c", "pclk";
		interrupts = <0x00 0x3a 0x04 0x00>;
		pinctrl-names = "default";
		pinctrl-0 = <0x8b>;
		#address-cells = <0x01>;
		#size-cells = <0x00>;
		status = "disabled";
		phandle = <0x100>;
	};

	pwm@ff420000 {
		compatible = "rockchip,rk3399-pwm", "rockchip,rk3288-pwm";
		reg = <0x00 0xff420000 0x00 0x10>;
		#pwm-cells = <0x03>;
		pinctrl-names = "default";
		pinctrl-0 = <0x8c>;
		clocks = <0x7e 0x1e>;
		status = "disabled";
		phandle = <0x101>;
	};

	pwm@ff420010 {
		compatible = "rockchip,rk3399-pwm", "rockchip,rk3288-pwm";
		reg = <0x00 0xff420010 0x00 0x10>;
		#pwm-cells = <0x03>;
		pinctrl-names = "default";
		pinctrl-0 = <0x8d>;
		clocks = <0x7e 0x1e>;
		status = "okay";
		phandle = <0x102>;
	};

	pwm@ff420020 {
		compatible = "rockchip,rk3399-pwm", "rockchip,rk3288-pwm";
		reg = <0x00 0xff420020 0x00 0x10>;
		#pwm-cells = <0x03>;
		pinctrl-names = "default";
		pinctrl-0 = <0x8e>;
		clocks = <0x7e 0x1e>;
		status = "okay";
		phandle = <0xc6>;
	};

	pwm@ff420030 {
		compatible = "rockchip,rk3399-pwm", "rockchip,rk3288-pwm";
		reg = <0x00 0xff420030 0x00 0x10>;
		#pwm-cells = <0x03>;
		pinctrl-names = "default";
		pinctrl-0 = <0x8f>;
		clocks = <0x7e 0x1e>;
		status = "disabled";
		phandle = <0x103>;
	};

	dfi@ff630000 {
		reg = <0x00 0xff630000 0x00 0x4000>;
		compatible = "rockchip,rk3399-dfi";
		rockchip,pmu = <0x11>;
		interrupts = <0x00 0x83 0x04 0x00>;
		clocks = <0x08 0x179>;
		clock-names = "pclk_ddr_mon";
		status = "disabled";
		phandle = <0x12>;
	};

	video-codec@ff650000 {
		compatible = "rockchip,rk3399-vpu";
		reg = <0x00 0xff650000 0x00 0x800>;
		interrupts = <0x00 0x72 0x04 0x00 0x00 0x71 0x04 0x00>;
		interrupt-names = "vepu", "vdpu";
		clocks = <0x08 0xeb 0x08 0x1ea>;
		clock-names = "aclk", "hclk";
		iommus = <0x90>;
		power-domains = <0x18 0x1f>;
		phandle = <0x104>;
	};

	iommu@ff650800 {
		compatible = "rockchip,iommu";
		reg = <0x00 0xff650800 0x00 0x40>;
		interrupts = <0x00 0x73 0x04 0x00>;
		clocks = <0x08 0xeb 0x08 0x1ea>;
		clock-names = "aclk", "iface";
		#iommu-cells = <0x00>;
		power-domains = <0x18 0x1f>;
		phandle = <0x90>;
	};

	video-codec@ff660000 {
		compatible = "rockchip,rk3399-vdec";
		reg = <0x00 0xff660000 0x00 0x480>;
		interrupts = <0x00 0x74 0x04 0x00>;
		clocks = <0x08 0xed 0x08 0x1ec 0x08 0x9f 0x08 0x9e>;
		clock-names = "axi", "ahb", "cabac", "core";
		iommus = <0x91>;
		power-domains = <0x18 0x20>;
		phandle = <0x105>;
	};

	iommu@ff660480 {
		compatible = "rockchip,iommu";
		reg = <0x00 0xff660480 0x00 0x40 0x00 0xff6604c0 0x00 0x40>;
		interrupts = <0x00 0x75 0x04 0x00>;
		clocks = <0x08 0xed 0x08 0x1ec>;
		clock-names = "aclk", "iface";
		power-domains = <0x18 0x20>;
		#iommu-cells = <0x00>;
		phandle = <0x91>;
	};

	iommu@ff670800 {
		compatible = "rockchip,iommu";
		reg = <0x00 0xff670800 0x00 0x40>;
		interrupts = <0x00 0x2a 0x04 0x00>;
		clocks = <0x08 0xe1 0x08 0x1dd>;
		clock-names = "aclk", "iface";
		#iommu-cells = <0x00>;
		status = "okay";
		phandle = <0x106>;
	};

	rga@ff680000 {
		compatible = "rockchip,rk3399-rga";
		reg = <0x00 0xff680000 0x00 0x10000>;
		interrupts = <0x00 0x37 0x04 0x00>;
		clocks = <0x08 0xdc 0x08 0x1e5 0x08 0x6d>;
		clock-names = "aclk", "hclk", "sclk";
		resets = <0x08 0x6a 0x08 0x67 0x08 0x69>;
		reset-names = "core", "axi", "ahb";
		power-domains = <0x18 0x21>;
		phandle = <0x107>;
	};

	efuse@ff690000 {
		compatible = "rockchip,rk3399-efuse";
		reg = <0x00 0xff690000 0x00 0x80>;
		#address-cells = <0x01>;
		#size-cells = <0x01>;
		clocks = <0x08 0x17d>;
		clock-names = "pclk_efuse";
		phandle = <0x108>;

		cpu-id@7 {
			reg = <0x07 0x10>;
			phandle = <0x109>;
		};

		cpu-leakage@17 {
			reg = <0x17 0x01>;
			phandle = <0x10a>;
		};

		gpu-leakage@18 {
			reg = <0x18 0x01>;
			phandle = <0x10b>;
		};

		center-leakage@19 {
			reg = <0x19 0x01>;
			phandle = <0x10c>;
		};

		cpu-leakage@1a {
			reg = <0x1a 0x01>;
			phandle = <0x10d>;
		};

		logic-leakage@1b {
			reg = <0x1b 0x01>;
			phandle = <0x10e>;
		};

		wafer-info@1c {
			reg = <0x1c 0x01>;
			phandle = <0x10f>;
		};
	};

	dma-controller@ff6d0000 {
		compatible = "arm,pl330", "arm,primecell";
		reg = <0x00 0xff6d0000 0x00 0x4000>;
		interrupts = <0x00 0x05 0x04 0x00 0x00 0x06 0x04 0x00>;
		#dma-cells = <0x01>;
		arm,pl330-periph-burst;
		clocks = <0x08 0xd3>;
		clock-names = "apb_pclk";
		phandle = <0x5c>;
	};

	dma-controller@ff6e0000 {
		compatible = "arm,pl330", "arm,primecell";
		reg = <0x00 0xff6e0000 0x00 0x4000>;
		interrupts = <0x00 0x07 0x04 0x00 0x00 0x08 0x04 0x00>;
		#dma-cells = <0x01>;
		arm,pl330-periph-burst;
		clocks = <0x08 0xd4>;
		clock-names = "apb_pclk";
		phandle = <0x4b>;
	};

	clock-controller@ff750000 {
		compatible = "rockchip,rk3399-pmucru";
		reg = <0x00 0xff750000 0x00 0x1000>;
		clocks = <0x92>;
		clock-names = "xin24m";
		rockchip,grf = <0x11>;
		#clock-cells = <0x01>;
		#reset-cells = <0x01>;
		assigned-clocks = <0x7e 0x01>;
		assigned-clock-rates = <0x284af100>;
		phandle = <0x7e>;
	};

	clock-controller@ff760000 {
		compatible = "rockchip,rk3399-cru";
		reg = <0x00 0xff760000 0x00 0x1000>;
		clocks = <0x92>;
		clock-names = "xin24m";
		rockchip,grf = <0x19>;
		#clock-cells = <0x01>;
		#reset-cells = <0x01>;
		assigned-clocks = <0x08 0x05 0x08 0x04 0x08 0x06 0x08 0xc0 0x08 0x1c0 0x08 0x140 0x08 0xc2 0x08 0x1c1 0x08 0x142 0x08 0xc9 0x08 0x1c2 0x08 0x143 0x08 0xe3 0x08 0xde 0x08 0x106 0x08 0x178 0x08 0xed>;
		assigned-clock-rates = <0x2367b880 0x2faf0800 0x3b9aca00 0x8f0d180 0x47868c0 0x23c3460 0x5f5e100 0x5f5e100 0x2faf080 0x23c34600 0x5f5e100 0x2faf080 0x17d78400 0x17d78400 0xbebc200 0xbebc200 0x17d78400>;
		phandle = <0x08>;
	};

	syscon@ff770000 {
		compatible = "rockchip,rk3399-grf", "syscon", "simple-mfd";
		reg = <0x00 0xff770000 0x00 0x10000>;
		#address-cells = <0x01>;
		#size-cells = <0x01>;
		phandle = <0x19>;

		io-domains {
			compatible = "rockchip,rk3399-io-voltage-domain";
			status = "okay";
			bt656-supply = <0x7d>;
			audio-supply = <0x93>;
			sdmmc-supply = <0x25>;
			gpio1830-supply = <0x7d>;
			phandle = <0x110>;
		};

		mipi-dphy-rx0 {
			compatible = "rockchip,rk3399-mipi-dphy-rx0";
			clocks = <0x08 0x77 0x08 0xa5 0x08 0x16f>;
			clock-names = "dphy-ref", "dphy-cfg", "grf";
			power-domains = <0x18 0x0f>;
			#phy-cells = <0x00>;
			status = "disabled";
			phandle = <0xa7>;
		};

		usb2phy@e450 {
			compatible = "rockchip,rk3399-usb2phy";
			reg = <0xe450 0x10>;
			clocks = <0x08 0x7b>;
			clock-names = "phyclk";
			#clock-cells = <0x00>;
			clock-output-names = "clk_usbphy0_480m";
			status = "okay";
			phandle = <0x2b>;

			host-port {
				#phy-cells = <0x00>;
				interrupts = <0x00 0x1b 0x04 0x00>;
				interrupt-names = "linestate";
				status = "okay";
				phy-supply = <0x94>;
				phandle = <0x2c>;
			};

			otg-port {
				#phy-cells = <0x00>;
				interrupts = <0x00 0x67 0x04 0x00 0x00 0x68 0x04 0x00 0x00 0x6a 0x04 0x00>;
				interrupt-names = "otg-bvalid", "otg-id", "linestate";
				status = "okay";
				phandle = <0x2f>;
			};
		};

		usb2phy@e460 {
			compatible = "rockchip,rk3399-usb2phy";
			reg = <0xe460 0x10>;
			clocks = <0x08 0x7c>;
			clock-names = "phyclk";
			#clock-cells = <0x00>;
			clock-output-names = "clk_usbphy1_480m";
			status = "okay";
			phandle = <0x2d>;

			host-port {
				#phy-cells = <0x00>;
				interrupts = <0x00 0x1f 0x04 0x00>;
				interrupt-names = "linestate";
				status = "okay";
				phy-supply = <0x94>;
				phandle = <0x2e>;
			};

			otg-port {
				#phy-cells = <0x00>;
				interrupts = <0x00 0x6c 0x04 0x00 0x00 0x6d 0x04 0x00 0x00 0x6f 0x04 0x00>;
				interrupt-names = "otg-bvalid", "otg-id", "linestate";
				status = "okay";
				phandle = <0x31>;
			};
		};

		phy@f780 {
			compatible = "rockchip,rk3399-emmc-phy";
			reg = <0xf780 0x24>;
			clocks = <0x95>;
			clock-names = "emmcclk";
			drive-impedance-ohm = <0x32>;
			#phy-cells = <0x00>;
			status = "okay";
			phandle = <0x2a>;
		};

		pcie-phy {
			compatible = "rockchip,rk3399-pcie-phy";
			clocks = <0x08 0x8a>;
			clock-names = "refclk";
			#phy-cells = <0x01>;
			resets = <0x08 0x87>;
			reset-names = "phy";
			status = "disabled";
			phandle = <0x17>;
		};
	};

	phy@ff7c0000 {
		compatible = "rockchip,rk3399-typec-phy";
		reg = <0x00 0xff7c0000 0x00 0x40000>;
		clocks = <0x08 0x7e 0x08 0x7d>;
		clock-names = "tcpdcore", "tcpdphy-ref";
		assigned-clocks = <0x08 0x7e>;
		assigned-clock-rates = <0x2faf080>;
		power-domains = <0x18 0x08>;
		resets = <0x08 0x95 0x08 0x94 0x08 0x14c>;
		reset-names = "uphy", "uphy-pipe", "uphy-tcphy";
		rockchip,grf = <0x19>;
		status = "okay";
		phandle = <0x111>;

		dp-port {
			#phy-cells = <0x00>;
			phandle = <0x33>;
		};

		usb3-port {
			#phy-cells = <0x00>;
			phandle = <0x30>;
		};
	};

	phy@ff800000 {
		compatible = "rockchip,rk3399-typec-phy";
		reg = <0x00 0xff800000 0x00 0x40000>;
		clocks = <0x08 0x80 0x08 0x7f>;
		clock-names = "tcpdcore", "tcpdphy-ref";
		assigned-clocks = <0x08 0x80>;
		assigned-clock-rates = <0x2faf080>;
		power-domains = <0x18 0x09>;
		resets = <0x08 0x9d 0x08 0x9c 0x08 0x14d>;
		reset-names = "uphy", "uphy-pipe", "uphy-tcphy";
		rockchip,grf = <0x19>;
		status = "okay";
		phandle = <0x112>;

		dp-port {
			#phy-cells = <0x00>;
			phandle = <0x34>;
		};

		usb3-port {
			#phy-cells = <0x00>;
			phandle = <0x32>;
		};
	};

	watchdog@ff848000 {
		compatible = "rockchip,rk3399-wdt", "snps,dw-wdt";
		reg = <0x00 0xff848000 0x00 0x100>;
		clocks = <0x08 0x17c>;
		interrupts = <0x00 0x78 0x04 0x00>;
	};

	rktimer@ff850000 {
		compatible = "rockchip,rk3399-timer";
		reg = <0x00 0xff850000 0x00 0x1000>;
		interrupts = <0x00 0x51 0x04 0x00>;
		clocks = <0x08 0x168 0x08 0x5a>;
		clock-names = "pclk", "timer";
		phandle = <0x113>;
	};

	spdif@ff870000 {
		compatible = "rockchip,rk3399-spdif";
		reg = <0x00 0xff870000 0x00 0x1000>;
		interrupts = <0x00 0x42 0x04 0x00>;
		dmas = <0x5c 0x07>;
		dma-names = "tx";
		clock-names = "mclk", "hclk";
		clocks = <0x08 0x55 0x08 0x1d7>;
		pinctrl-names = "default";
		pinctrl-0 = <0x96>;
		power-domains = <0x18 0x1c>;
		#sound-dai-cells = <0x00>;
		status = "disabled";
		phandle = <0x114>;
	};

	i2s@ff880000 {
		compatible = "rockchip,rk3399-i2s", "rockchip,rk3066-i2s";
		reg = <0x00 0xff880000 0x00 0x1000>;
		rockchip,grf = <0x19>;
		interrupts = <0x00 0x27 0x04 0x00>;
		dmas = <0x5c 0x00 0x5c 0x01>;
		dma-names = "tx", "rx";
		clock-names = "i2s_clk", "i2s_hclk";
		clocks = <0x08 0x56 0x08 0x1d4>;
		pinctrl-names = "bclk_on", "bclk_off";
		pinctrl-0 = <0x97>;
		pinctrl-1 = <0x98>;
		power-domains = <0x18 0x1c>;
		#sound-dai-cells = <0x00>;
		status = "disabled";
		phandle = <0x115>;
	};

	i2s@ff890000 {
		compatible = "rockchip,rk3399-i2s", "rockchip,rk3066-i2s";
		reg = <0x00 0xff890000 0x00 0x1000>;
		interrupts = <0x00 0x28 0x04 0x00>;
		dmas = <0x5c 0x02 0x5c 0x03>;
		dma-names = "tx", "rx";
		clock-names = "i2s_clk", "i2s_hclk";
		clocks = <0x08 0x57 0x08 0x1d5>;
		pinctrl-names = "default";
		pinctrl-0 = <0x99>;
		power-domains = <0x18 0x1c>;
		#sound-dai-cells = <0x00>;
		status = "disabled";
		phandle = <0x116>;
	};

	i2s@ff8a0000 {
		compatible = "rockchip,rk3399-i2s", "rockchip,rk3066-i2s";
		reg = <0x00 0xff8a0000 0x00 0x1000>;
		interrupts = <0x00 0x29 0x04 0x00>;
		dmas = <0x5c 0x04 0x5c 0x05>;
		dma-names = "tx", "rx";
		clock-names = "i2s_clk", "i2s_hclk";
		clocks = <0x08 0x58 0x08 0x1d6>;
		power-domains = <0x18 0x1c>;
		#sound-dai-cells = <0x00>;
		status = "okay";
		phandle = <0xaa>;
	};

	vop@ff8f0000 {
		compatible = "rockchip,rk3399-vop-lit";
		reg = <0x00 0xff8f0000 0x00 0x2000 0x00 0xff8f2000 0x00 0x400>;
		interrupts = <0x00 0x77 0x04 0x00>;
		assigned-clocks = <0x08 0xdb 0x08 0x1db>;
		assigned-clock-rates = <0x17d78400 0x5f5e100>;
		clocks = <0x08 0xdb 0x08 0xb5 0x08 0x1db>;
		clock-names = "aclk_vop", "dclk_vop", "hclk_vop";
		iommus = <0x9a>;
		power-domains = <0x18 0x12>;
		resets = <0x08 0x113 0x08 0x117 0x08 0x119>;
		reset-names = "axi", "ahb", "dclk";
		status = "okay";
		phandle = <0x117>;

		port {
			#address-cells = <0x01>;
			#size-cells = <0x00>;
			phandle = <0x0f>;

			endpoint@0 {
				reg = <0x00>;
				remote-endpoint = <0x9b>;
				phandle = <0xb1>;
			};

			endpoint@1 {
				reg = <0x01>;
				remote-endpoint = <0x9c>;
				phandle = <0xb6>;
			};

			endpoint@2 {
				reg = <0x02>;
				remote-endpoint = <0x9d>;
				phandle = <0xaf>;
			};

			endpoint@3 {
				reg = <0x03>;
				remote-endpoint = <0x9e>;
				phandle = <0xb3>;
			};

			endpoint@4 {
				reg = <0x04>;
				remote-endpoint = <0x9f>;
				phandle = <0x36>;
			};
		};
	};

	iommu@ff8f3f00 {
		compatible = "rockchip,iommu";
		reg = <0x00 0xff8f3f00 0x00 0x100>;
		interrupts = <0x00 0x77 0x04 0x00>;
		clocks = <0x08 0xdb 0x08 0x1db>;
		clock-names = "aclk", "iface";
		power-domains = <0x18 0x12>;
		#iommu-cells = <0x00>;
		status = "okay";
		phandle = <0x9a>;
	};

	vop@ff900000 {
		compatible = "rockchip,rk3399-vop-big";
		reg = <0x00 0xff900000 0x00 0x2000 0x00 0xff902000 0x00 0x1000>;
		interrupts = <0x00 0x76 0x04 0x00>;
		assigned-clocks = <0x08 0xd9 0x08 0x1d9>;
		assigned-clock-rates = <0x17d78400 0x5f5e100>;
		clocks = <0x08 0xd9 0x08 0xb4 0x08 0x1d9>;
		clock-names = "aclk_vop", "dclk_vop", "hclk_vop";
		iommus = <0xa0>;
		power-domains = <0x18 0x11>;
		resets = <0x08 0x112 0x08 0x116 0x08 0x118>;
		reset-names = "axi", "ahb", "dclk";
		status = "okay";
		phandle = <0x118>;

		port {
			#address-cells = <0x01>;
			#size-cells = <0x00>;
			phandle = <0x10>;

			endpoint@0 {
				reg = <0x00>;
				remote-endpoint = <0xa1>;
				phandle = <0xb5>;
			};

			endpoint@1 {
				reg = <0x01>;
				remote-endpoint = <0xa2>;
				phandle = <0xb0>;
			};

			endpoint@2 {
				reg = <0x02>;
				remote-endpoint = <0xa3>;
				phandle = <0xae>;
			};

			endpoint@3 {
				reg = <0x03>;
				remote-endpoint = <0xa4>;
				phandle = <0xb2>;
			};

			endpoint@4 {
				reg = <0x04>;
				remote-endpoint = <0xa5>;
				phandle = <0x35>;
			};
		};
	};

	iommu@ff903f00 {
		compatible = "rockchip,iommu";
		reg = <0x00 0xff903f00 0x00 0x100>;
		interrupts = <0x00 0x76 0x04 0x00>;
		clocks = <0x08 0xd9 0x08 0x1d9>;
		clock-names = "aclk", "iface";
		power-domains = <0x18 0x11>;
		#iommu-cells = <0x00>;
		status = "okay";
		phandle = <0xa0>;
	};

	isp0@ff910000 {
		compatible = "rockchip,rk3399-cif-isp";
		reg = <0x00 0xff910000 0x00 0x4000>;
		interrupts = <0x00 0x2b 0x04 0x00>;
		clocks = <0x08 0x6e 0x08 0xe9 0x08 0x1e3>;
		clock-names = "isp", "aclk", "hclk";
		iommus = <0xa6>;
		phys = <0xa7>;
		phy-names = "dphy";
		power-domains = <0x18 0x13>;
		status = "disabled";
		phandle = <0x119>;

		ports {
			#address-cells = <0x01>;
			#size-cells = <0x00>;

			port@0 {
				reg = <0x00>;
				#address-cells = <0x01>;
				#size-cells = <0x00>;
			};
		};
	};

	iommu@ff914000 {
		compatible = "rockchip,iommu";
		reg = <0x00 0xff914000 0x00 0x100 0x00 0xff915000 0x00 0x100>;
		interrupts = <0x00 0x2b 0x04 0x00>;
		clocks = <0x08 0xe9 0x08 0x1e3>;
		clock-names = "aclk", "iface";
		#iommu-cells = <0x00>;
		power-domains = <0x18 0x13>;
		rockchip,disable-mmu-reset;
		phandle = <0xa6>;
	};

	isp1@ff920000 {
		compatible = "rockchip,rk3399-cif-isp";
		reg = <0x00 0xff920000 0x00 0x4000>;
		interrupts = <0x00 0x2c 0x04 0x00>;
		clocks = <0x08 0x6f 0x08 0xea 0x08 0x1e4>;
		clock-names = "isp", "aclk", "hclk";
		iommus = <0xa8>;
		phys = <0xa9>;
		phy-names = "dphy";
		power-domains = <0x18 0x14>;
		status = "disabled";
		phandle = <0x11a>;

		ports {
			#address-cells = <0x01>;
			#size-cells = <0x00>;

			port@0 {
				reg = <0x00>;
				#address-cells = <0x01>;
				#size-cells = <0x00>;
			};
		};
	};

	iommu@ff924000 {
		compatible = "rockchip,iommu";
		reg = <0x00 0xff924000 0x00 0x100 0x00 0xff925000 0x00 0x100>;
		interrupts = <0x00 0x2c 0x04 0x00>;
		clocks = <0x08 0xea 0x08 0x1e4>;
		clock-names = "aclk", "iface";
		#iommu-cells = <0x00>;
		power-domains = <0x18 0x14>;
		rockchip,disable-mmu-reset;
		phandle = <0xa8>;
	};

	hdmi-sound {
		compatible = "simple-audio-card";
		simple-audio-card,format = "i2s";
		simple-audio-card,mclk-fs = <0x100>;
		simple-audio-card,name = "hdmi-sound";
		status = "okay";
		phandle = <0x11b>;

		simple-audio-card,cpu {
			sound-dai = <0xaa>;
		};

		simple-audio-card,codec {
			sound-dai = <0xab>;
		};
	};

	hdmi@ff940000 {
		compatible = "rockchip,rk3399-dw-hdmi";
		reg = <0x00 0xff940000 0x00 0x20000>;
		reg-io-width = <0x04>;
		interrupts = <0x00 0x17 0x04 0x00>;
		clocks = <0x08 0x174 0x08 0x71 0x08 0x70 0x08 0x16f 0x08 0x07>;
		clock-names = "iahb", "isfr", "cec", "grf", "ref";
		power-domains = <0x18 0x15>;
		rockchip,grf = <0x19>;
		#sound-dai-cells = <0x00>;
		status = "okay";
		ddc-i2c-bus = <0xac>;
		pinctrl-names = "default";
		pinctrl-0 = <0xad>;
		phandle = <0xab>;

		ports {
			#address-cells = <0x01>;
			#size-cells = <0x00>;

			port@0 {
				reg = <0x00>;
				#address-cells = <0x01>;
				#size-cells = <0x00>;
				phandle = <0x11c>;

				endpoint@0 {
					reg = <0x00>;
					remote-endpoint = <0xae>;
					phandle = <0xa3>;
				};

				endpoint@1 {
					reg = <0x01>;
					remote-endpoint = <0xaf>;
					phandle = <0x9d>;
				};
			};

			port@1 {
				reg = <0x01>;
				phandle = <0x11d>;
			};
		};
	};

	mipi@ff960000 {
		compatible = "rockchip,rk3399-mipi-dsi", "snps,dw-mipi-dsi";
		reg = <0x00 0xff960000 0x00 0x8000>;
		interrupts = <0x00 0x2d 0x04 0x00>;
		clocks = <0x08 0xa2 0x08 0x170 0x08 0xa3 0x08 0x16f>;
		clock-names = "ref", "pclk", "phy_cfg", "grf";
		power-domains = <0x18 0x0f>;
		resets = <0x08 0xfb>;
		reset-names = "apb";
		rockchip,grf = <0x19>;
		#address-cells = <0x01>;
		#size-cells = <0x00>;
		status = "disabled";
		phandle = <0x11e>;

		ports {
			#address-cells = <0x01>;
			#size-cells = <0x00>;

			port@0 {
				reg = <0x00>;
				#address-cells = <0x01>;
				#size-cells = <0x00>;
				phandle = <0x11f>;

				endpoint@0 {
					reg = <0x00>;
					remote-endpoint = <0xb0>;
					phandle = <0xa2>;
				};

				endpoint@1 {
					reg = <0x01>;
					remote-endpoint = <0xb1>;
					phandle = <0x9b>;
				};
			};
		};
	};

	mipi@ff968000 {
		compatible = "rockchip,rk3399-mipi-dsi", "snps,dw-mipi-dsi";
		reg = <0x00 0xff968000 0x00 0x8000>;
		interrupts = <0x00 0x2e 0x04 0x00>;
		clocks = <0x08 0xa2 0x08 0x171 0x08 0xa4 0x08 0x16f>;
		clock-names = "ref", "pclk", "phy_cfg", "grf";
		power-domains = <0x18 0x0f>;
		resets = <0x08 0xfc>;
		reset-names = "apb";
		rockchip,grf = <0x19>;
		#address-cells = <0x01>;
		#size-cells = <0x00>;
		#phy-cells = <0x00>;
		status = "disabled";
		phandle = <0xa9>;

		ports {
			#address-cells = <0x01>;
			#size-cells = <0x00>;

			port@0 {
				reg = <0x00>;
				#address-cells = <0x01>;
				#size-cells = <0x00>;
				phandle = <0x120>;

				endpoint@0 {
					reg = <0x00>;
					remote-endpoint = <0xb2>;
					phandle = <0xa4>;
				};

				endpoint@1 {
					reg = <0x01>;
					remote-endpoint = <0xb3>;
					phandle = <0x9e>;
				};
			};
		};
	};

	edp@ff970000 {
		compatible = "rockchip,rk3399-edp";
		reg = <0x00 0xff970000 0x00 0x8000>;
		interrupts = <0x00 0x0a 0x04 0x00>;
		clocks = <0x08 0x16a 0x08 0x16c 0x08 0x16f>;
		clock-names = "dp", "pclk", "grf";
		pinctrl-names = "default";
		pinctrl-0 = <0xb4>;
		power-domains = <0x18 0x19>;
		resets = <0x08 0x11d>;
		reset-names = "dp";
		rockchip,grf = <0x19>;
		status = "disabled";
		phandle = <0x121>;

		ports {
			#address-cells = <0x01>;
			#size-cells = <0x00>;

			port@0 {
				reg = <0x00>;
				#address-cells = <0x01>;
				#size-cells = <0x00>;
				phandle = <0x122>;

				endpoint@0 {
					reg = <0x00>;
					remote-endpoint = <0xb5>;
					phandle = <0xa1>;
				};

				endpoint@1 {
					reg = <0x01>;
					remote-endpoint = <0xb6>;
					phandle = <0x9c>;
				};
			};
		};
	};

	rng@ff8b8000 {
		compatible = "rockchip,cryptov1-rng";
		reg = <0x00 0xff8b8000 0x00 0x1000>;
		clocks = <0x08 0x86 0x08 0x1d3>;
		clock-names = "clk_crypto", "hclk_crypto";
		assigned-clocks = <0x08 0x86 0x08 0x1d3>;
		assigned-clock-rates = <0x8f0d180 0x5f5e100>;
		status = "okay";
		phandle = <0x123>;
	};

	gpu@ff9a0000 {
		compatible = "rockchip,rk3399-mali", "arm,mali-t860";
		reg = <0x00 0xff9a0000 0x00 0x10000>;
		interrupts = <0x00 0x14 0x04 0x00 0x00 0x15 0x04 0x00 0x00 0x13 0x04 0x00>;
		interrupt-names = "job", "mmu", "gpu";
		clocks = <0x08 0xd0>;
		#cooling-cells = <0x02>;
		power-domains = <0x18 0x23>;
		status = "okay";
		operating-points-v2 = <0xb7>;
		mali-supply = <0xb8>;
		phandle = <0x65>;
	};

	pinctrl {
		compatible = "rockchip,rk3399-pinctrl";
		rockchip,grf = <0x19>;
		rockchip,pmu = <0x11>;
		#address-cells = <0x02>;
		#size-cells = <0x02>;
		ranges;
		phandle = <0x124>;

		gpio@ff720000 {
			compatible = "rockchip,gpio-bank";
			reg = <0x00 0xff720000 0x00 0x100>;
			clocks = <0x7e 0x17>;
			interrupts = <0x00 0x0e 0x04 0x00>;
			gpio-controller;
			#gpio-cells = <0x02>;
			interrupt-controller;
			#interrupt-cells = <0x02>;
			phandle = <0x22>;
		};

		gpio@ff730000 {
			compatible = "rockchip,gpio-bank";
			reg = <0x00 0xff730000 0x00 0x100>;
			clocks = <0x7e 0x18>;
			interrupts = <0x00 0x0f 0x04 0x00>;
			gpio-controller;
			#gpio-cells = <0x02>;
			interrupt-controller;
			#interrupt-cells = <0x02>;
			phandle = <0x85>;
		};

		gpio@ff780000 {
			compatible = "rockchip,gpio-bank";
			reg = <0x00 0xff780000 0x00 0x100>;
			clocks = <0x08 0x150>;
			interrupts = <0x00 0x10 0x04 0x00>;
			gpio-controller;
			#gpio-cells = <0x02>;
			interrupt-controller;
			#interrupt-cells = <0x02>;
			phandle = <0x42>;
		};

		gpio@ff788000 {
			compatible = "rockchip,gpio-bank";
			reg = <0x00 0xff788000 0x00 0x100>;
			clocks = <0x08 0x151>;
			interrupts = <0x00 0x11 0x04 0x00>;
			gpio-controller;
			#gpio-cells = <0x02>;
			interrupt-controller;
			#interrupt-cells = <0x02>;
			phandle = <0x1d>;
		};

		gpio@ff790000 {
			compatible = "rockchip,gpio-bank";
			reg = <0x00 0xff790000 0x00 0x100>;
			clocks = <0x08 0x152>;
			interrupts = <0x00 0x12 0x04 0x00>;
			gpio-controller;
			#gpio-cells = <0x02>;
			interrupt-controller;
			#interrupt-cells = <0x02>;
			phandle = <0xc1>;
		};

		pcfg-pull-up {
			bias-pull-up;
			phandle = <0xbd>;
		};

		pcfg-pull-down {
			bias-pull-down;
			phandle = <0xbe>;
		};

		pcfg-pull-none {
			bias-disable;
			phandle = <0xb9>;
		};

		pcfg-pull-none-12ma {
			bias-disable;
			drive-strength = <0x0c>;
			phandle = <0xbc>;
		};

		pcfg-pull-none-13ma {
			bias-disable;
			drive-strength = <0x0d>;
			phandle = <0xba>;
		};

		pcfg-pull-none-18ma {
			bias-disable;
			drive-strength = <0x12>;
			phandle = <0x125>;
		};

		pcfg-pull-none-20ma {
			bias-disable;
			drive-strength = <0x14>;
			phandle = <0x126>;
		};

		pcfg-pull-up-2ma {
			bias-pull-up;
			drive-strength = <0x02>;
			phandle = <0x127>;
		};

		pcfg-pull-up-8ma {
			bias-pull-up;
			drive-strength = <0x08>;
			phandle = <0x128>;
		};

		pcfg-pull-up-18ma {
			bias-pull-up;
			drive-strength = <0x12>;
			phandle = <0x129>;
		};

		pcfg-pull-up-20ma {
			bias-pull-up;
			drive-strength = <0x14>;
			phandle = <0x12a>;
		};

		pcfg-pull-down-4ma {
			bias-pull-down;
			drive-strength = <0x04>;
			phandle = <0x12b>;
		};

		pcfg-pull-down-8ma {
			bias-pull-down;
			drive-strength = <0x08>;
			phandle = <0x12c>;
		};

		pcfg-pull-down-12ma {
			bias-pull-down;
			drive-strength = <0x0c>;
			phandle = <0x12d>;
		};

		pcfg-pull-down-18ma {
			bias-pull-down;
			drive-strength = <0x12>;
			phandle = <0x12e>;
		};

		pcfg-pull-down-20ma {
			bias-pull-down;
			drive-strength = <0x14>;
			phandle = <0x12f>;
		};

		pcfg-output-high {
			output-high;
			phandle = <0x130>;
		};

		pcfg-output-low {
			output-low;
			phandle = <0xbb>;
		};

		pcfg-input-enable {
			input-enable;
			phandle = <0x131>;
		};

		pcfg-input-pull-up {
			input-enable;
			bias-pull-up;
			phandle = <0x132>;
		};

		pcfg-input-pull-down {
			input-enable;
			bias-pull-down;
			phandle = <0x133>;
		};

		clock {

			clk-32k {
				rockchip,pins = <0x00 0x00 0x02 0xb9>;
				phandle = <0x134>;
			};
		};

		cif {

			cif-clkin {
				rockchip,pins = <0x02 0x0a 0x03 0xb9>;
				phandle = <0x135>;
			};

			cif-clkouta {
				rockchip,pins = <0x02 0x0b 0x03 0xb9>;
				phandle = <0x136>;
			};
		};

		edp {

			edp-hpd {
				rockchip,pins = <0x04 0x17 0x02 0xb9>;
				phandle = <0xb4>;
			};
		};

		gmac {

			rgmii-pins {
				rockchip,pins = <0x03 0x11 0x01 0xba 0x03 0x0e 0x01 0xb9 0x03 0x0d 0x01 0xb9 0x03 0x0c 0x01 0xba 0x03 0x0b 0x01 0xb9 0x03 0x09 0x01 0xb9 0x03 0x08 0x01 0xb9 0x03 0x07 0x01 0xb9 0x03 0x06 0x01 0xb9 0x03 0x05 0x01 0xba 0x03 0x04 0x01 0xba 0x03 0x03 0x01 0xb9 0x03 0x02 0x01 0xb9 0x03 0x01 0x01 0xba 0x03 0x00 0x01 0xba>;
				phandle = <0x1c>;
			};

			rmii-pins {
				rockchip,pins = <0x03 0x0d 0x01 0xb9 0x03 0x0c 0x01 0xba 0x03 0x0b 0x01 0xb9 0x03 0x0a 0x01 0xb9 0x03 0x09 0x01 0xb9 0x03 0x08 0x01 0xb9 0x03 0x07 0x01 0xb9 0x03 0x06 0x01 0xb9 0x03 0x05 0x01 0xba 0x03 0x04 0x01 0xba>;
				phandle = <0x137>;
			};

			rgmii-sleep-pins {
				rockchip,pins = <0x03 0x0f 0x00 0xbb>;
				phandle = <0x138>;
			};
		};

		i2c0 {

			i2c0-xfer {
				rockchip,pins = <0x01 0x0f 0x02 0xb9 0x01 0x10 0x02 0xb9>;
				phandle = <0x84>;
			};
		};

		i2c1 {

			i2c1-xfer {
				rockchip,pins = <0x04 0x02 0x01 0xb9 0x04 0x01 0x01 0xb9>;
				phandle = <0x38>;
			};
		};

		i2c2 {

			i2c2-xfer {
				rockchip,pins = <0x02 0x01 0x02 0xbc 0x02 0x00 0x02 0xbc>;
				phandle = <0x39>;
			};
		};

		i2c3 {

			i2c3-xfer {
				rockchip,pins = <0x04 0x11 0x01 0xb9 0x04 0x10 0x01 0xb9>;
				phandle = <0x3a>;
			};
		};

		i2c4 {

			i2c4-xfer {
				rockchip,pins = <0x01 0x0c 0x01 0xb9 0x01 0x0b 0x01 0xb9>;
				phandle = <0x8a>;
			};
		};

		i2c5 {

			i2c5-xfer {
				rockchip,pins = <0x03 0x0b 0x02 0xb9 0x03 0x0a 0x02 0xb9>;
				phandle = <0x3b>;
			};
		};

		i2c6 {

			i2c6-xfer {
				rockchip,pins = <0x02 0x0a 0x02 0xb9 0x02 0x09 0x02 0xb9>;
				phandle = <0x3c>;
			};
		};

		i2c7 {

			i2c7-xfer {
				rockchip,pins = <0x02 0x08 0x02 0xb9 0x02 0x07 0x02 0xb9>;
				phandle = <0x3d>;
			};
		};

		i2c8 {

			i2c8-xfer {
				rockchip,pins = <0x01 0x15 0x01 0xb9 0x01 0x14 0x01 0xb9>;
				phandle = <0x8b>;
			};
		};

		i2s0 {

			i2s0-2ch-bus {
				rockchip,pins = <0x03 0x18 0x01 0xb9 0x03 0x19 0x01 0xb9 0x03 0x1a 0x01 0xb9 0x03 0x1b 0x01 0xb9 0x03 0x1f 0x01 0xb9 0x04 0x00 0x01 0xb9>;
				phandle = <0x139>;
			};

			i2s0-2ch-bus-bclk-off {
				rockchip,pins = <0x03 0x18 0x00 0xb9 0x03 0x19 0x01 0xb9 0x03 0x1a 0x01 0xb9 0x03 0x1b 0x01 0xb9 0x03 0x1f 0x01 0xb9 0x04 0x00 0x01 0xb9>;
				phandle = <0x13a>;
			};

			i2s0-8ch-bus {
				rockchip,pins = <0x03 0x18 0x01 0xb9 0x03 0x19 0x01 0xb9 0x03 0x1a 0x01 0xb9 0x03 0x1b 0x01 0xb9 0x03 0x1c 0x01 0xb9 0x03 0x1d 0x01 0xb9 0x03 0x1e 0x01 0xb9 0x03 0x1f 0x01 0xb9 0x04 0x00 0x01 0xb9>;
				phandle = <0x97>;
			};

			i2s0-8ch-bus-bclk-off {
				rockchip,pins = <0x03 0x18 0x00 0xb9 0x03 0x19 0x01 0xb9 0x03 0x1a 0x01 0xb9 0x03 0x1b 0x01 0xb9 0x03 0x1c 0x01 0xb9 0x03 0x1d 0x01 0xb9 0x03 0x1e 0x01 0xb9 0x03 0x1f 0x01 0xb9 0x04 0x00 0x01 0xb9>;
				phandle = <0x98>;
			};
		};

		i2s1 {

			i2s1-2ch-bus {
				rockchip,pins = <0x04 0x03 0x01 0xb9 0x04 0x04 0x01 0xb9 0x04 0x05 0x01 0xb9 0x04 0x06 0x01 0xb9 0x04 0x07 0x01 0xb9>;
				phandle = <0x99>;
			};

			i2s1-2ch-bus-bclk-off {
				rockchip,pins = <0x04 0x03 0x00 0xb9 0x04 0x04 0x01 0xb9 0x04 0x05 0x01 0xb9 0x04 0x06 0x01 0xb9 0x04 0x07 0x01 0xb9>;
				phandle = <0x13b>;
			};
		};

		sdio0 {

			sdio0-bus1 {
				rockchip,pins = <0x02 0x14 0x01 0xbd>;
				phandle = <0x13c>;
			};

			sdio0-bus4 {
				rockchip,pins = <0x02 0x14 0x01 0xbd 0x02 0x15 0x01 0xbd 0x02 0x16 0x01 0xbd 0x02 0x17 0x01 0xbd>;
				phandle = <0x1f>;
			};

			sdio0-cmd {
				rockchip,pins = <0x02 0x18 0x01 0xbd>;
				phandle = <0x20>;
			};

			sdio0-clk {
				rockchip,pins = <0x02 0x19 0x01 0xb9>;
				phandle = <0x21>;
			};

			sdio0-cd {
				rockchip,pins = <0x02 0x1a 0x01 0xbd>;
				phandle = <0x13d>;
			};

			sdio0-pwr {
				rockchip,pins = <0x02 0x1b 0x01 0xbd>;
				phandle = <0x13e>;
			};

			sdio0-bkpwr {
				rockchip,pins = <0x02 0x1c 0x01 0xbd>;
				phandle = <0x13f>;
			};

			sdio0-wp {
				rockchip,pins = <0x00 0x03 0x01 0xbd>;
				phandle = <0x140>;
			};

			sdio0-int {
				rockchip,pins = <0x00 0x04 0x01 0xbd>;
				phandle = <0x141>;
			};
		};

		sdmmc {

			sdmmc-bus1 {
				rockchip,pins = <0x04 0x08 0x01 0xbd>;
				phandle = <0x142>;
			};

			sdmmc-bus4 {
				rockchip,pins = <0x04 0x08 0x01 0xbd 0x04 0x09 0x01 0xbd 0x04 0x0a 0x01 0xbd 0x04 0x0b 0x01 0xbd>;
				phandle = <0x29>;
			};

			sdmmc-clk {
				rockchip,pins = <0x04 0x0c 0x01 0xb9>;
				phandle = <0x26>;
			};

			sdmmc-cmd {
				rockchip,pins = <0x04 0x0d 0x01 0xbd>;
				phandle = <0x27>;
			};

			sdmmc-cd {
				rockchip,pins = <0x00 0x07 0x01 0xbd>;
				phandle = <0x28>;
			};

			sdmmc-wp {
				rockchip,pins = <0x00 0x08 0x01 0xbd>;
				phandle = <0x143>;
			};
		};

		suspend {

			ap-pwroff {
				rockchip,pins = <0x01 0x05 0x01 0xb9>;
				phandle = <0x144>;
			};

			ddrio-pwroff {
				rockchip,pins = <0x00 0x01 0x01 0xb9>;
				phandle = <0x145>;
			};
		};

		spdif {

			spdif-bus {
				rockchip,pins = <0x04 0x15 0x01 0xb9>;
				phandle = <0x96>;
			};

			spdif-bus-1 {
				rockchip,pins = <0x03 0x10 0x03 0xb9>;
				phandle = <0x146>;
			};
		};

		spi0 {

			spi0-clk {
				rockchip,pins = <0x03 0x06 0x02 0xbd>;
				phandle = <0x4c>;
			};

			spi0-cs0 {
				rockchip,pins = <0x03 0x07 0x02 0xbd>;
				phandle = <0x4f>;
			};

			spi0-cs1 {
				rockchip,pins = <0x03 0x08 0x02 0xbd>;
				phandle = <0x147>;
			};

			spi0-tx {
				rockchip,pins = <0x03 0x05 0x02 0xbd>;
				phandle = <0x4d>;
			};

			spi0-rx {
				rockchip,pins = <0x03 0x04 0x02 0xbd>;
				phandle = <0x4e>;
			};
		};

		spi1 {

			spi1-clk {
				rockchip,pins = <0x01 0x09 0x02 0xbd>;
				phandle = <0x50>;
			};

			spi1-cs0 {
				rockchip,pins = <0x01 0x0a 0x02 0xbd>;
				phandle = <0x53>;
			};

			spi1-rx {
				rockchip,pins = <0x01 0x07 0x02 0xbd>;
				phandle = <0x52>;
			};

			spi1-tx {
				rockchip,pins = <0x01 0x08 0x02 0xbd>;
				phandle = <0x51>;
			};
		};

		spi2 {

			spi2-clk {
				rockchip,pins = <0x02 0x0b 0x01 0xbd>;
				phandle = <0x54>;
			};

			spi2-cs0 {
				rockchip,pins = <0x02 0x0c 0x01 0xbd>;
				phandle = <0x57>;
			};

			spi2-rx {
				rockchip,pins = <0x02 0x09 0x01 0xbd>;
				phandle = <0x56>;
			};

			spi2-tx {
				rockchip,pins = <0x02 0x0a 0x01 0xbd>;
				phandle = <0x55>;
			};
		};

		spi3 {

			spi3-clk {
				rockchip,pins = <0x01 0x11 0x01 0xbd>;
				phandle = <0x7f>;
			};

			spi3-cs0 {
				rockchip,pins = <0x01 0x12 0x01 0xbd>;
				phandle = <0x82>;
			};

			spi3-rx {
				rockchip,pins = <0x01 0x0f 0x01 0xbd>;
				phandle = <0x81>;
			};

			spi3-tx {
				rockchip,pins = <0x01 0x10 0x01 0xbd>;
				phandle = <0x80>;
			};
		};

		spi4 {

			spi4-clk {
				rockchip,pins = <0x03 0x02 0x02 0xbd>;
				phandle = <0x58>;
			};

			spi4-cs0 {
				rockchip,pins = <0x03 0x03 0x02 0xbd>;
				phandle = <0x5b>;
			};

			spi4-rx {
				rockchip,pins = <0x03 0x00 0x02 0xbd>;
				phandle = <0x5a>;
			};

			spi4-tx {
				rockchip,pins = <0x03 0x01 0x02 0xbd>;
				phandle = <0x59>;
			};
		};

		spi5 {

			spi5-clk {
				rockchip,pins = <0x02 0x16 0x02 0xbd>;
				phandle = <0x5d>;
			};

			spi5-cs0 {
				rockchip,pins = <0x02 0x17 0x02 0xbd>;
				phandle = <0x60>;
			};

			spi5-rx {
				rockchip,pins = <0x02 0x14 0x02 0xbd>;
				phandle = <0x5f>;
			};

			spi5-tx {
				rockchip,pins = <0x02 0x15 0x02 0xbd>;
				phandle = <0x5e>;
			};
		};

		testclk {

			test-clkout0 {
				rockchip,pins = <0x00 0x00 0x01 0xb9>;
				phandle = <0x148>;
			};

			test-clkout1 {
				rockchip,pins = <0x02 0x19 0x02 0xb9>;
				phandle = <0x149>;
			};

			test-clkout2 {
				rockchip,pins = <0x00 0x08 0x03 0xb9>;
				phandle = <0x14a>;
			};
		};

		tsadc {

			otp-pin {
				rockchip,pins = <0x01 0x06 0x00 0xb9>;
				phandle = <0x66>;
			};

			otp-out {
				rockchip,pins = <0x01 0x06 0x01 0xb9>;
				phandle = <0x67>;
			};
		};

		uart0 {

			uart0-xfer {
				rockchip,pins = <0x02 0x10 0x01 0xbd 0x02 0x11 0x01 0xb9>;
				phandle = <0x3e>;
			};

			uart0-cts {
				rockchip,pins = <0x02 0x12 0x01 0xb9>;
				phandle = <0x3f>;
			};

			uart0-rts {
				rockchip,pins = <0x02 0x13 0x01 0xb9>;
				phandle = <0x40>;
			};
		};

		uart1 {

			uart1-xfer {
				rockchip,pins = <0x03 0x0c 0x02 0xbd 0x03 0x0d 0x02 0xb9>;
				phandle = <0x48>;
			};
		};

		uart2a {

			uart2a-xfer {
				rockchip,pins = <0x04 0x08 0x02 0xbd 0x04 0x09 0x02 0xb9>;
				phandle = <0x14b>;
			};
		};

		uart2b {

			uart2b-xfer {
				rockchip,pins = <0x04 0x10 0x02 0xbd 0x04 0x11 0x02 0xb9>;
				phandle = <0x14c>;
			};
		};

		uart2c {

			uart2c-xfer {
				rockchip,pins = <0x04 0x13 0x01 0xbd 0x04 0x14 0x01 0xb9>;
				phandle = <0x49>;
			};
		};

		uart3 {

			uart3-xfer {
				rockchip,pins = <0x03 0x0e 0x02 0xbd 0x03 0x0f 0x02 0xb9>;
				phandle = <0x4a>;
			};

			uart3-cts {
				rockchip,pins = <0x03 0x10 0x02 0xb9>;
				phandle = <0x14d>;
			};

			uart3-rts {
				rockchip,pins = <0x03 0x11 0x02 0xb9>;
				phandle = <0x14e>;
			};
		};

		uart4 {

			uart4-xfer {
				rockchip,pins = <0x01 0x07 0x01 0xbd 0x01 0x08 0x01 0xb9>;
				phandle = <0x83>;
			};
		};

		uarthdcp {

			uarthdcp-xfer {
				rockchip,pins = <0x04 0x15 0x02 0xbd 0x04 0x16 0x02 0xb9>;
				phandle = <0x14f>;
			};
		};

		pwm0 {

			pwm0-pin {
				rockchip,pins = <0x04 0x12 0x01 0xb9>;
				phandle = <0x8c>;
			};

			pwm0-pin-pull-down {
				rockchip,pins = <0x04 0x12 0x01 0xbe>;
				phandle = <0x150>;
			};

			vop0-pwm-pin {
				rockchip,pins = <0x04 0x12 0x02 0xb9>;
				phandle = <0x151>;
			};

			vop1-pwm-pin {
				rockchip,pins = <0x04 0x12 0x03 0xb9>;
				phandle = <0x152>;
			};
		};

		pwm1 {

			pwm1-pin {
				rockchip,pins = <0x04 0x16 0x01 0xb9>;
				phandle = <0x8d>;
			};

			pwm1-pin-pull-down {
				rockchip,pins = <0x04 0x16 0x01 0xbe>;
				phandle = <0x153>;
			};
		};

		pwm2 {

			pwm2-pin {
				rockchip,pins = <0x01 0x13 0x01 0xb9>;
				phandle = <0x8e>;
			};

			pwm2-pin-pull-down {
				rockchip,pins = <0x01 0x13 0x01 0xbe>;
				phandle = <0x154>;
			};
		};

		pwm3a {

			pwm3a-pin {
				rockchip,pins = <0x00 0x06 0x01 0xb9>;
				phandle = <0x8f>;
			};
		};

		pwm3b {

			pwm3b-pin {
				rockchip,pins = <0x01 0x0e 0x01 0xb9>;
				phandle = <0x155>;
			};
		};

		hdmi {

			hdmi-i2c-xfer {
				rockchip,pins = <0x04 0x11 0x03 0xb9 0x04 0x10 0x03 0xb9>;
				phandle = <0x156>;
			};

			hdmi-cec {
				rockchip,pins = <0x04 0x17 0x01 0xb9>;
				phandle = <0xad>;
			};
		};

		pcie {

			pci-clkreqn-cpm {
				rockchip,pins = <0x02 0x1a 0x00 0xb9>;
				phandle = <0x157>;
			};

			pci-clkreqnb-cpm {
				rockchip,pins = <0x04 0x18 0x00 0xb9>;
				phandle = <0x158>;
			};
		};

		bt {

			bt-enable-h {
				rockchip,pins = <0x00 0x09 0x00 0xb9>;
				phandle = <0x45>;
			};

			bt-host-wake-l {
				rockchip,pins = <0x00 0x04 0x00 0xbe>;
				phandle = <0x43>;
			};

			bt-wake-l {
				rockchip,pins = <0x02 0x1a 0x00 0xb9>;
				phandle = <0x44>;
			};
		};

		wifi {

			wifi-host-wake-l {
				rockchip,pins = <0x00 0x03 0x00 0xb9>;
				phandle = <0x23>;
			};
		};

		buttons {

			pwrbtn {
				rockchip,pins = <0x00 0x05 0x00 0xbd>;
				phandle = <0xbf>;
			};
		};

		pmic {

			pmic-int-l {
				rockchip,pins = <0x01 0x15 0x00 0xbd>;
				phandle = <0x86>;
			};

			vsel1-pin {
				rockchip,pins = <0x01 0x11 0x00 0xbe>;
				phandle = <0x87>;
			};

			vsel2-pin {
				rockchip,pins = <0x01 0x0e 0x00 0xbe>;
				phandle = <0x89>;
			};
		};

		sdio-pwrseq {

			wifi-enable-h {
				rockchip,pins = <0x00 0x0a 0x00 0xb9>;
				phandle = <0xc0>;
			};
		};

		usb {

			vcc5v0-host-en {
				rockchip,pins = <0x04 0x1c 0x00 0xb9>;
				phandle = <0xc3>;
			};

			usb2-hub-en {
				rockchip,pins = <0x01 0x00 0x00 0xbd>;
				phandle = <0xc4>;
			};
		};

		headphone {

			spk-ctl {
				rockchip,pins = <0x04 0x15 0x00 0xb9>;
				phandle = <0x159>;
			};

			spk-pwr {
				rockchip,pins = <0x01 0x09 0x00 0xb9>;
				phandle = <0x15a>;
			};
		};

		bl_ctrl {

			bl-en {
				rockchip,pins = <0x04 0x1d 0x00 0xb9>;
				phandle = <0x15b>;
			};

			vcc-lcd-en {
				rockchip,pins = <0x01 0x03 0x00 0xbd>;
				phandle = <0xc2>;
			};
		};
	};

	opp-table-0 {
		compatible = "operating-points-v2";
		opp-shared;
		phandle = <0x0b>;

		opp00 {
			opp-hz = <0x00 0x18519600>;
			opp-microvolt = <0xc96a8 0xc96a8 0x1312d0>;
			clock-latency-ns = <0x9c40>;
		};

		opp01 {
			opp-hz = <0x00 0x23c34600>;
			opp-microvolt = <0xc96a8 0xc96a8 0x1312d0>;
		};

		opp02 {
			opp-hz = <0x00 0x30a32c00>;
			opp-microvolt = <0xcf850 0xcf850 0x1312d0>;
		};

		opp03 {
			opp-hz = <0x00 0x3c14dc00>;
			opp-microvolt = <0xe1d48 0xe1d48 0x1312d0>;
		};

		opp04 {
			opp-hz = <0x00 0x47868c00>;
			opp-microvolt = <0xf4240 0xf4240 0x1312d0>;
		};

		opp05 {
			opp-hz = <0x00 0x54667200>;
			opp-microvolt = <0x112a88 0x112a88 0x1312d0>;
		};
	};

	opp-table-1 {
		compatible = "operating-points-v2";
		opp-shared;
		phandle = <0x0d>;

		opp00 {
			opp-hz = <0x00 0x18519600>;
			opp-microvolt = <0xc96a8 0xc96a8 0x1312d0>;
			clock-latency-ns = <0x9c40>;
		};

		opp01 {
			opp-hz = <0x00 0x23c34600>;
			opp-microvolt = <0xc96a8 0xc96a8 0x1312d0>;
		};

		opp02 {
			opp-hz = <0x00 0x30a32c00>;
			opp-microvolt = <0xc96a8 0xc96a8 0x1312d0>;
		};

		opp03 {
			opp-hz = <0x00 0x3c14dc00>;
			opp-microvolt = <0xd59f8 0xd59f8 0x1312d0>;
		};

		opp04 {
			opp-hz = <0x00 0x47868c00>;
			opp-microvolt = <0xe7ef0 0xe7ef0 0x1312d0>;
		};

		opp05 {
			opp-hz = <0x00 0x54667200>;
			opp-microvolt = <0xfa3e8 0xfa3e8 0x1312d0>;
		};

		opp06 {
			opp-hz = <0x00 0x5fd82200>;
			opp-microvolt = <0x10c8e0 0x10c8e0 0x1312d0>;
		};

		opp07 {
			opp-hz = <0x00 0x6b49d200>;
			opp-microvolt = <0x124f80 0x124f80 0x1312d0>;
		};
	};

	opp-table-2 {
		compatible = "operating-points-v2";
		phandle = <0xb7>;

		opp00 {
			opp-hz = <0x00 0xbebc200>;
			opp-microvolt = <0xc96a8 0xc96a8 0x118c30>;
		};

		opp01 {
			opp-hz = <0x00 0x11b3dc40>;
			opp-microvolt = <0xc96a8 0xc96a8 0x118c30>;
		};

		opp02 {
			opp-hz = <0x00 0x17d78400>;
			opp-microvolt = <0xc96a8 0xc96a8 0x118c30>;
		};

		opp03 {
			opp-hz = <0x00 0x1dcd6500>;
			opp-microvolt = <0xd59f8 0xd59f8 0x118c30>;
		};

		opp04 {
			opp-hz = <0x00 0x23c34600>;
			opp-microvolt = <0xe1d48 0xe1d48 0x118c30>;
		};

		opp05 {
			opp-hz = <0x00 0x2faf0800>;
			opp-microvolt = <0x10c8e0 0x10c8e0 0x118c30>;
		};
	};

	chosen {
		stdout-path = "serial2:1500000n8";
	};

	board-info {
		compatible = "board-info";
		pmic-reset = <0x85 0x06 0x00>;
		phandle = <0x15c>;
	};

	external-gmac-clock {
		compatible = "fixed-clock";
		clock-frequency = <0x7735940>;
		clock-output-names = "clkin_gmac";
		#clock-cells = <0x00>;
		phandle = <0x1a>;
	};

	gpio-keys {
		compatible = "gpio-keys";
		autorepeat;
		pinctrl-names = "default";
		pinctrl-0 = <0xbf>;

		key-power {
			debounce-interval = <0x64>;
			gpios = <0x22 0x05 0x01>;
			label = "GPIO Key Power";
			linux,code = <0x74>;
			wakeup-source;
		};
	};

	sdio-pwrseq {
		compatible = "mmc-pwrseq-simple";
		clocks = <0x41 0x01>;
		clock-names = "ext_clock";
		pinctrl-names = "default";
		pinctrl-0 = <0xc0>;
		reset-gpios = <0x22 0x0a 0x01>;
		phandle = <0x1e>;
	};

	vcc12v-dcin {
		compatible = "regulator-fixed";
		regulator-name = "vcc12v_dcin";
		regulator-always-on;
		regulator-boot-on;
		regulator-min-microvolt = <0xb71b00>;
		regulator-max-microvolt = <0xb71b00>;
		phandle = <0xc5>;
	};

	vcc-lcd {
		compatible = "regulator-fixed";
		enable-active-high;
		gpio = <0xc1 0x1e 0x00>;
		pinctrl-names = "default";
		pinctrl-0 = <0xc2>;
		regulator-name = "vcc_lcd";
		regulator-always-on;
		phandle = <0x15d>;
	};

	vccadc-ref {
		compatible = "regulator-fixed";
		regulator-name = "vcc1v8_sys";
		regulator-always-on;
		regulator-boot-on;
		regulator-min-microvolt = <0x1b7740>;
		regulator-max-microvolt = <0x1b7740>;
		phandle = <0x37>;
	};

	vcc-phy-regulator {
		compatible = "regulator-fixed";
		regulator-name = "vcc_phy";
		regulator-always-on;
		regulator-boot-on;
		phandle = <0x1b>;
	};

	vcc-sd {
		compatible = "regulator-fixed";
		regulator-name = "vcc_sd";
		regulator-always-on;
		regulator-boot-on;
		regulator-min-microvolt = <0x325aa0>;
		regulator-max-microvolt = <0x325aa0>;
		vin-supply = <0x88>;
		phandle = <0x24>;
	};

	vcc3v3-sys {
		compatible = "regulator-fixed";
		regulator-name = "vcc3v3_sys";
		regulator-always-on;
		regulator-boot-on;
		regulator-min-microvolt = <0x325aa0>;
		regulator-max-microvolt = <0x325aa0>;
		vin-supply = <0x88>;
		phandle = <0x46>;
	};

	vcc5v0-host-regulator {
		compatible = "regulator-fixed";
		enable-active-high;
		gpio = <0xc1 0x1c 0x00>;
		pinctrl-names = "default";
		pinctrl-0 = <0xc3>;
		regulator-name = "vcc5v0_host";
		regulator-always-on;
		vin-supply = <0x88>;
		phandle = <0x94>;
	};

	usb2-hub-en {
		compatible = "regulator-fixed";
		enable-active-high;
		gpio = <0x85 0x00 0x00>;
		pinctrl-names = "default";
		pinctrl-0 = <0xc4>;
		regulator-name = "usb2_hub";
		regulator-always-on;
		phandle = <0x15e>;
	};

	vcc5v0-sys {
		compatible = "regulator-fixed";
		regulator-name = "vcc5v0_sys";
		regulator-always-on;
		regulator-boot-on;
		regulator-min-microvolt = <0x4c4b40>;
		regulator-max-microvolt = <0x4c4b40>;
		vin-supply = <0xc5>;
		phandle = <0x88>;
	};

	vdd-log {
		compatible = "pwm-regulator";
		pwms = <0xc6 0x00 0x61a8 0x01>;
		pwm-supply = <0x88>;
		regulator-name = "vdd_log";
		regulator-always-on;
		regulator-boot-on;
		regulator-min-microvolt = "", "\f5";
		regulator-max-microvolt = <0x19f0a0>;
		phandle = <0x15f>;
	};

	__symbols__ {
		cpu_l0 = "/cpus/cpu@0";
		cpu_l1 = "/cpus/cpu@1";
		cpu_l2 = "/cpus/cpu@2";
		cpu_l3 = "/cpus/cpu@3";
		cpu_b0 = "/cpus/cpu@100";
		cpu_b1 = "/cpus/cpu@101";
		CPU_SLEEP = "/cpus/idle-states/cpu-sleep";
		CLUSTER_SLEEP = "/cpus/idle-states/cluster-sleep";
		dmc = "/memory-controller";
		xin24m = "/xin24m";
		pcie0 = "/pcie@f8000000";
		pcie0_intc = "/pcie@f8000000/interrupt-controller";
		gmac = "/ethernet@fe300000";
		sdio0 = "/mmc@fe310000";
		brcmf = "/mmc@fe310000/wifi@1";
		sdmmc = "/mmc@fe320000";
		sdhci = "/mmc@fe330000";
		usb_host0_ehci = "/usb@fe380000";
		usb_host0_ohci = "/usb@fe3a0000";
		usb_host1_ehci = "/usb@fe3c0000";
		usb_host1_ohci = "/usb@fe3e0000";
		usbdrd3_0 = "/usb@fe800000";
		usbdrd_dwc3_0 = "/usb@fe800000/usb@fe800000";
		usbdrd3_1 = "/usb@fe900000";
		usbdrd_dwc3_1 = "/usb@fe900000/usb@fe900000";
		cdn_dp = "/dp@fec00000";
		dp_in = "/dp@fec00000/ports/port";
		dp_in_vopb = "/dp@fec00000/ports/port/endpoint@0";
		dp_in_vopl = "/dp@fec00000/ports/port/endpoint@1";
		gic = "/interrupt-controller@fee00000";
		its = "/interrupt-controller@fee00000/interrupt-controller@fee20000";
		ppi_cluster0 = "/interrupt-controller@fee00000/ppi-partitions/interrupt-partition-0";
		ppi_cluster1 = "/interrupt-controller@fee00000/ppi-partitions/interrupt-partition-1";
		saradc = "/saradc@ff100000";
		crypto0 = "/crypto@ff8b0000";
		crypto1 = "/crypto@ff8b8000";
		i2c1 = "/i2c@ff110000";
		i2c2 = "/i2c@ff120000";
		i2c3 = "/i2c@ff130000";
		i2c5 = "/i2c@ff140000";
		i2c6 = "/i2c@ff150000";
		i2c7 = "/i2c@ff160000";
		uart0 = "/serial@ff180000";
		uart1 = "/serial@ff190000";
		uart2 = "/serial@ff1a0000";
		uart3 = "/serial@ff1b0000";
		spi0 = "/spi@ff1c0000";
		spi1 = "/spi@ff1d0000";
		spi2 = "/spi@ff1e0000";
		spi4 = "/spi@ff1f0000";
		spi5 = "/spi@ff200000";
		thermal_zones = "/thermal-zones";
		cpu_thermal = "/thermal-zones/cpu-thermal";
		cpu_alert0 = "/thermal-zones/cpu-thermal/trips/cpu_alert0";
		cpu_alert1 = "/thermal-zones/cpu-thermal/trips/cpu_alert1";
		cpu_crit = "/thermal-zones/cpu-thermal/trips/cpu_crit";
		gpu_thermal = "/thermal-zones/gpu-thermal";
		gpu_alert0 = "/thermal-zones/gpu-thermal/trips/gpu_alert0";
		gpu_crit = "/thermal-zones/gpu-thermal/trips/gpu_crit";
		tsadc = "/tsadc@ff260000";
		qos_emmc = "/qos@ffa58000";
		qos_gmac = "/qos@ffa5c000";
		qos_pcie = "/qos@ffa60080";
		qos_usb_host0 = "/qos@ffa60100";
		qos_usb_host1 = "/qos@ffa60180";
		qos_usb_otg0 = "/qos@ffa70000";
		qos_usb_otg1 = "/qos@ffa70080";
		qos_sd = "/qos@ffa74000";
		qos_sdioaudio = "/qos@ffa76000";
		qos_hdcp = "/qos@ffa90000";
		qos_iep = "/qos@ffa98000";
		qos_isp0_m0 = "/qos@ffaa0000";
		qos_isp0_m1 = "/qos@ffaa0080";
		qos_isp1_m0 = "/qos@ffaa8000";
		qos_isp1_m1 = "/qos@ffaa8080";
		qos_rga_r = "/qos@ffab0000";
		qos_rga_w = "/qos@ffab0080";
		qos_video_m0 = "/qos@ffab8000";
		qos_video_m1_r = "/qos@ffac0000";
		qos_video_m1_w = "/qos@ffac0080";
		qos_vop_big_r = "/qos@ffac8000";
		qos_vop_big_w = "/qos@ffac8080";
		qos_vop_little = "/qos@ffad0000";
		qos_perihp = "/qos@ffad8080";
		qos_gpu = "/qos@ffae0000";
		pmu = "/power-management@ff310000";
		power = "/power-management@ff310000/power-controller";
		pmugrf = "/syscon@ff320000";
		pmu_io_domains = "/syscon@ff320000/io-domains";
		spi3 = "/spi@ff350000";
		uart4 = "/serial@ff370000";
		i2c0 = "/i2c@ff3c0000";
		rk808 = "/i2c@ff3c0000/pmic@1b";
		vdd_center = "/i2c@ff3c0000/pmic@1b/regulators/DCDC_REG1";
		vdd_cpu_l = "/i2c@ff3c0000/pmic@1b/regulators/DCDC_REG2";
		vcc_ddr = "/i2c@ff3c0000/pmic@1b/regulators/DCDC_REG3";
		vcc_1v8 = "/i2c@ff3c0000/pmic@1b/regulators/DCDC_REG4";
		vcc1v8_dvp = "/i2c@ff3c0000/pmic@1b/regulators/LDO_REG1";
		vcc3v0_tp = "/i2c@ff3c0000/pmic@1b/regulators/LDO_REG2";
		vcc1v8_pmu = "/i2c@ff3c0000/pmic@1b/regulators/LDO_REG3";
		vccio_sd = "/i2c@ff3c0000/pmic@1b/regulators/LDO_REG4";
		vcca3v0_codec = "/i2c@ff3c0000/pmic@1b/regulators/LDO_REG5";
		vcc_1v5 = "/i2c@ff3c0000/pmic@1b/regulators/LDO_REG6";
		vcca1v8_codec = "/i2c@ff3c0000/pmic@1b/regulators/LDO_REG7";
		vcc_3v0 = "/i2c@ff3c0000/pmic@1b/regulators/LDO_REG8";
		vcc3v3_s3 = "/i2c@ff3c0000/pmic@1b/regulators/SWITCH_REG1";
		vcc3v3_s0 = "/i2c@ff3c0000/pmic@1b/regulators/SWITCH_REG2";
		vdd_cpu_b = "/i2c@ff3c0000/regulator@40";
		vdd_gpu = "/i2c@ff3c0000/regulator@41";
		i2c4 = "/i2c@ff3d0000";
		i2c8 = "/i2c@ff3e0000";
		pwm0 = "/pwm@ff420000";
		pwm1 = "/pwm@ff420010";
		pwm2 = "/pwm@ff420020";
		pwm3 = "/pwm@ff420030";
		dfi = "/dfi@ff630000";
		vpu = "/video-codec@ff650000";
		vpu_mmu = "/iommu@ff650800";
		vdec = "/video-codec@ff660000";
		vdec_mmu = "/iommu@ff660480";
		iep_mmu = "/iommu@ff670800";
		rga = "/rga@ff680000";
		efuse0 = "/efuse@ff690000";
		cpu_id = "/efuse@ff690000/cpu-id@7";
		cpub_leakage = "/efuse@ff690000/cpu-leakage@17";
		gpu_leakage = "/efuse@ff690000/gpu-leakage@18";
		center_leakage = "/efuse@ff690000/center-leakage@19";
		cpul_leakage = "/efuse@ff690000/cpu-leakage@1a";
		logic_leakage = "/efuse@ff690000/logic-leakage@1b";
		wafer_info = "/efuse@ff690000/wafer-info@1c";
		dmac_bus = "/dma-controller@ff6d0000";
		dmac_peri = "/dma-controller@ff6e0000";
		pmucru = "/clock-controller@ff750000";
		cru = "/clock-controller@ff760000";
		grf = "/syscon@ff770000";
		io_domains = "/syscon@ff770000/io-domains";
		mipi_dphy_rx0 = "/syscon@ff770000/mipi-dphy-rx0";
		u2phy0 = "/syscon@ff770000/usb2phy@e450";
		u2phy0_host = "/syscon@ff770000/usb2phy@e450/host-port";
		u2phy0_otg = "/syscon@ff770000/usb2phy@e450/otg-port";
		u2phy1 = "/syscon@ff770000/usb2phy@e460";
		u2phy1_host = "/syscon@ff770000/usb2phy@e460/host-port";
		u2phy1_otg = "/syscon@ff770000/usb2phy@e460/otg-port";
		emmc_phy = "/syscon@ff770000/phy@f780";
		pcie_phy = "/syscon@ff770000/pcie-phy";
		tcphy0 = "/phy@ff7c0000";
		tcphy0_dp = "/phy@ff7c0000/dp-port";
		tcphy0_usb3 = "/phy@ff7c0000/usb3-port";
		tcphy1 = "/phy@ff800000";
		tcphy1_dp = "/phy@ff800000/dp-port";
		tcphy1_usb3 = "/phy@ff800000/usb3-port";
		rktimer = "/rktimer@ff850000";
		spdif = "/spdif@ff870000";
		i2s0 = "/i2s@ff880000";
		i2s1 = "/i2s@ff890000";
		i2s2 = "/i2s@ff8a0000";
		vopl = "/vop@ff8f0000";
		vopl_out = "/vop@ff8f0000/port";
		vopl_out_mipi = "/vop@ff8f0000/port/endpoint@0";
		vopl_out_edp = "/vop@ff8f0000/port/endpoint@1";
		vopl_out_hdmi = "/vop@ff8f0000/port/endpoint@2";
		vopl_out_mipi1 = "/vop@ff8f0000/port/endpoint@3";
		vopl_out_dp = "/vop@ff8f0000/port/endpoint@4";
		vopl_mmu = "/iommu@ff8f3f00";
		vopb = "/vop@ff900000";
		vopb_out = "/vop@ff900000/port";
		vopb_out_edp = "/vop@ff900000/port/endpoint@0";
		vopb_out_mipi = "/vop@ff900000/port/endpoint@1";
		vopb_out_hdmi = "/vop@ff900000/port/endpoint@2";
		vopb_out_mipi1 = "/vop@ff900000/port/endpoint@3";
		vopb_out_dp = "/vop@ff900000/port/endpoint@4";
		vopb_mmu = "/iommu@ff903f00";
		isp0 = "/isp0@ff910000";
		isp0_mmu = "/iommu@ff914000";
		isp1 = "/isp1@ff920000";
		isp1_mmu = "/iommu@ff924000";
		hdmi_sound = "/hdmi-sound";
		hdmi = "/hdmi@ff940000";
		hdmi_in = "/hdmi@ff940000/ports/port@0";
		hdmi_in_vopb = "/hdmi@ff940000/ports/port@0/endpoint@0";
		hdmi_in_vopl = "/hdmi@ff940000/ports/port@0/endpoint@1";
		hdmi_out = "/hdmi@ff940000/ports/port@1";
		mipi_dsi = "/mipi@ff960000";
		mipi_in = "/mipi@ff960000/ports/port@0";
		mipi_in_vopb = "/mipi@ff960000/ports/port@0/endpoint@0";
		mipi_in_vopl = "/mipi@ff960000/ports/port@0/endpoint@1";
		mipi_dsi1 = "/mipi@ff968000";
		mipi1_in = "/mipi@ff968000/ports/port@0";
		mipi1_in_vopb = "/mipi@ff968000/ports/port@0/endpoint@0";
		mipi1_in_vopl = "/mipi@ff968000/ports/port@0/endpoint@1";
		edp = "/edp@ff970000";
		edp_in = "/edp@ff970000/ports/port@0";
		edp_in_vopb = "/edp@ff970000/ports/port@0/endpoint@0";
		edp_in_vopl = "/edp@ff970000/ports/port@0/endpoint@1";
		rng = "/rng@ff8b8000";
		gpu = "/gpu@ff9a0000";
		pinctrl = "/pinctrl";
		gpio0 = "/pinctrl/gpio@ff720000";
		gpio1 = "/pinctrl/gpio@ff730000";
		gpio2 = "/pinctrl/gpio@ff780000";
		gpio3 = "/pinctrl/gpio@ff788000";
		gpio4 = "/pinctrl/gpio@ff790000";
		pcfg_pull_up = "/pinctrl/pcfg-pull-up";
		pcfg_pull_down = "/pinctrl/pcfg-pull-down";
		pcfg_pull_none = "/pinctrl/pcfg-pull-none";
		pcfg_pull_none_12ma = "/pinctrl/pcfg-pull-none-12ma";
		pcfg_pull_none_13ma = "/pinctrl/pcfg-pull-none-13ma";
		pcfg_pull_none_18ma = "/pinctrl/pcfg-pull-none-18ma";
		pcfg_pull_none_20ma = "/pinctrl/pcfg-pull-none-20ma";
		pcfg_pull_up_2ma = "/pinctrl/pcfg-pull-up-2ma";
		pcfg_pull_up_8ma = "/pinctrl/pcfg-pull-up-8ma";
		pcfg_pull_up_18ma = "/pinctrl/pcfg-pull-up-18ma";
		pcfg_pull_up_20ma = "/pinctrl/pcfg-pull-up-20ma";
		pcfg_pull_down_4ma = "/pinctrl/pcfg-pull-down-4ma";
		pcfg_pull_down_8ma = "/pinctrl/pcfg-pull-down-8ma";
		pcfg_pull_down_12ma = "/pinctrl/pcfg-pull-down-12ma";
		pcfg_pull_down_18ma = "/pinctrl/pcfg-pull-down-18ma";
		pcfg_pull_down_20ma = "/pinctrl/pcfg-pull-down-20ma";
		pcfg_output_high = "/pinctrl/pcfg-output-high";
		pcfg_output_low = "/pinctrl/pcfg-output-low";
		pcfg_input_enable = "/pinctrl/pcfg-input-enable";
		pcfg_input_pull_up = "/pinctrl/pcfg-input-pull-up";
		pcfg_input_pull_down = "/pinctrl/pcfg-input-pull-down";
		clk_32k = "/pinctrl/clock/clk-32k";
		cif_clkin = "/pinctrl/cif/cif-clkin";
		cif_clkouta = "/pinctrl/cif/cif-clkouta";
		edp_hpd = "/pinctrl/edp/edp-hpd";
		rgmii_pins = "/pinctrl/gmac/rgmii-pins";
		rmii_pins = "/pinctrl/gmac/rmii-pins";
		rgmii_sleep_pins = "/pinctrl/gmac/rgmii-sleep-pins";
		i2c0_xfer = "/pinctrl/i2c0/i2c0-xfer";
		i2c1_xfer = "/pinctrl/i2c1/i2c1-xfer";
		i2c2_xfer = "/pinctrl/i2c2/i2c2-xfer";
		i2c3_xfer = "/pinctrl/i2c3/i2c3-xfer";
		i2c4_xfer = "/pinctrl/i2c4/i2c4-xfer";
		i2c5_xfer = "/pinctrl/i2c5/i2c5-xfer";
		i2c6_xfer = "/pinctrl/i2c6/i2c6-xfer";
		i2c7_xfer = "/pinctrl/i2c7/i2c7-xfer";
		i2c8_xfer = "/pinctrl/i2c8/i2c8-xfer";
		i2s0_2ch_bus = "/pinctrl/i2s0/i2s0-2ch-bus";
		i2s0_2ch_bus_bclk_off = "/pinctrl/i2s0/i2s0-2ch-bus-bclk-off";
		i2s0_8ch_bus = "/pinctrl/i2s0/i2s0-8ch-bus";
		i2s0_8ch_bus_bclk_off = "/pinctrl/i2s0/i2s0-8ch-bus-bclk-off";
		i2s1_2ch_bus = "/pinctrl/i2s1/i2s1-2ch-bus";
		i2s1_2ch_bus_bclk_off = "/pinctrl/i2s1/i2s1-2ch-bus-bclk-off";
		sdio0_bus1 = "/pinctrl/sdio0/sdio0-bus1";
		sdio0_bus4 = "/pinctrl/sdio0/sdio0-bus4";
		sdio0_cmd = "/pinctrl/sdio0/sdio0-cmd";
		sdio0_clk = "/pinctrl/sdio0/sdio0-clk";
		sdio0_cd = "/pinctrl/sdio0/sdio0-cd";
		sdio0_pwr = "/pinctrl/sdio0/sdio0-pwr";
		sdio0_bkpwr = "/pinctrl/sdio0/sdio0-bkpwr";
		sdio0_wp = "/pinctrl/sdio0/sdio0-wp";
		sdio0_int = "/pinctrl/sdio0/sdio0-int";
		sdmmc_bus1 = "/pinctrl/sdmmc/sdmmc-bus1";
		sdmmc_bus4 = "/pinctrl/sdmmc/sdmmc-bus4";
		sdmmc_clk = "/pinctrl/sdmmc/sdmmc-clk";
		sdmmc_cmd = "/pinctrl/sdmmc/sdmmc-cmd";
		sdmmc_cd = "/pinctrl/sdmmc/sdmmc-cd";
		sdmmc_wp = "/pinctrl/sdmmc/sdmmc-wp";
		ap_pwroff = "/pinctrl/suspend/ap-pwroff";
		ddrio_pwroff = "/pinctrl/suspend/ddrio-pwroff";
		spdif_bus = "/pinctrl/spdif/spdif-bus";
		spdif_bus_1 = "/pinctrl/spdif/spdif-bus-1";
		spi0_clk = "/pinctrl/spi0/spi0-clk";
		spi0_cs0 = "/pinctrl/spi0/spi0-cs0";
		spi0_cs1 = "/pinctrl/spi0/spi0-cs1";
		spi0_tx = "/pinctrl/spi0/spi0-tx";
		spi0_rx = "/pinctrl/spi0/spi0-rx";
		spi1_clk = "/pinctrl/spi1/spi1-clk";
		spi1_cs0 = "/pinctrl/spi1/spi1-cs0";
		spi1_rx = "/pinctrl/spi1/spi1-rx";
		spi1_tx = "/pinctrl/spi1/spi1-tx";
		spi2_clk = "/pinctrl/spi2/spi2-clk";
		spi2_cs0 = "/pinctrl/spi2/spi2-cs0";
		spi2_rx = "/pinctrl/spi2/spi2-rx";
		spi2_tx = "/pinctrl/spi2/spi2-tx";
		spi3_clk = "/pinctrl/spi3/spi3-clk";
		spi3_cs0 = "/pinctrl/spi3/spi3-cs0";
		spi3_rx = "/pinctrl/spi3/spi3-rx";
		spi3_tx = "/pinctrl/spi3/spi3-tx";
		spi4_clk = "/pinctrl/spi4/spi4-clk";
		spi4_cs0 = "/pinctrl/spi4/spi4-cs0";
		spi4_rx = "/pinctrl/spi4/spi4-rx";
		spi4_tx = "/pinctrl/spi4/spi4-tx";
		spi5_clk = "/pinctrl/spi5/spi5-clk";
		spi5_cs0 = "/pinctrl/spi5/spi5-cs0";
		spi5_rx = "/pinctrl/spi5/spi5-rx";
		spi5_tx = "/pinctrl/spi5/spi5-tx";
		test_clkout0 = "/pinctrl/testclk/test-clkout0";
		test_clkout1 = "/pinctrl/testclk/test-clkout1";
		test_clkout2 = "/pinctrl/testclk/test-clkout2";
		otp_pin = "/pinctrl/tsadc/otp-pin";
		otp_out = "/pinctrl/tsadc/otp-out";
		uart0_xfer = "/pinctrl/uart0/uart0-xfer";
		uart0_cts = "/pinctrl/uart0/uart0-cts";
		uart0_rts = "/pinctrl/uart0/uart0-rts";
		uart1_xfer = "/pinctrl/uart1/uart1-xfer";
		uart2a_xfer = "/pinctrl/uart2a/uart2a-xfer";
		uart2b_xfer = "/pinctrl/uart2b/uart2b-xfer";
		uart2c_xfer = "/pinctrl/uart2c/uart2c-xfer";
		uart3_xfer = "/pinctrl/uart3/uart3-xfer";
		uart3_cts = "/pinctrl/uart3/uart3-cts";
		uart3_rts = "/pinctrl/uart3/uart3-rts";
		uart4_xfer = "/pinctrl/uart4/uart4-xfer";
		uarthdcp_xfer = "/pinctrl/uarthdcp/uarthdcp-xfer";
		pwm0_pin = "/pinctrl/pwm0/pwm0-pin";
		pwm0_pin_pull_down = "/pinctrl/pwm0/pwm0-pin-pull-down";
		vop0_pwm_pin = "/pinctrl/pwm0/vop0-pwm-pin";
		vop1_pwm_pin = "/pinctrl/pwm0/vop1-pwm-pin";
		pwm1_pin = "/pinctrl/pwm1/pwm1-pin";
		pwm1_pin_pull_down = "/pinctrl/pwm1/pwm1-pin-pull-down";
		pwm2_pin = "/pinctrl/pwm2/pwm2-pin";
		pwm2_pin_pull_down = "/pinctrl/pwm2/pwm2-pin-pull-down";
		pwm3a_pin = "/pinctrl/pwm3a/pwm3a-pin";
		pwm3b_pin = "/pinctrl/pwm3b/pwm3b-pin";
		hdmi_i2c_xfer = "/pinctrl/hdmi/hdmi-i2c-xfer";
		hdmi_cec = "/pinctrl/hdmi/hdmi-cec";
		pcie_clkreqn_cpm = "/pinctrl/pcie/pci-clkreqn-cpm";
		pcie_clkreqnb_cpm = "/pinctrl/pcie/pci-clkreqnb-cpm";
		bt_enable_h = "/pinctrl/bt/bt-enable-h";
		bt_host_wake_l = "/pinctrl/bt/bt-host-wake-l";
		bt_wake_l = "/pinctrl/bt/bt-wake-l";
		wifi_host_wake_l = "/pinctrl/wifi/wifi-host-wake-l";
		pwrbtn = "/pinctrl/buttons/pwrbtn";
		pmic_int_l = "/pinctrl/pmic/pmic-int-l";
		vsel1_pin = "/pinctrl/pmic/vsel1-pin";
		vsel2_pin = "/pinctrl/pmic/vsel2-pin";
		wifi_enable_h = "/pinctrl/sdio-pwrseq/wifi-enable-h";
		vcc5v0_host_en = "/pinctrl/usb/vcc5v0-host-en";
		usb2_hub_en = "/pinctrl/usb/usb2-hub-en";
		spk_ctl = "/pinctrl/headphone/spk-ctl";
		spk_pwr = "/pinctrl/headphone/spk-pwr";
		bl_en = "/pinctrl/bl_ctrl/bl-en";
		vcc_lcd_en = "/pinctrl/bl_ctrl/vcc-lcd-en";
		cluster0_opp = "/opp-table-0";
		cluster1_opp = "/opp-table-1";
		gpu_opp_table = "/opp-table-2";
		board_info = "/board-info";
		clkin_gmac = "/external-gmac-clock";
		sdio_pwrseq = "/sdio-pwrseq";
		vcc12v_dcin = "/vcc12v-dcin";
		vcc_lcd = "/vcc-lcd";
		vccadc_ref = "/vccadc-ref";
		vcc_phy = "/vcc-phy-regulator";
		vcc_sd = "/vcc-sd";
		vcc3v3_sys = "/vcc3v3-sys";
		vcc5v0_host = "/vcc5v0-host-regulator";
		usb2_hub = "/usb2-hub-en";
		vcc5v0_sys = "/vcc5v0-sys";
		vdd_log = "/vdd-log";
	};
};
